VERSION ""

NS_ :

BS_:

BU_: Vector__XXX

BO_ 2416478208 M001_WriteStartLTCTransmission: 8 Vector__XXX
SG_ M001_FixValues_LockIDPageCommand : 0|24@1+ (1,0) [0|16777215] "" Vector__XXX
SG_ M001_LockIDPageCommand : 24|8@1+ (1,0) [0|255] "" Vector__XXX

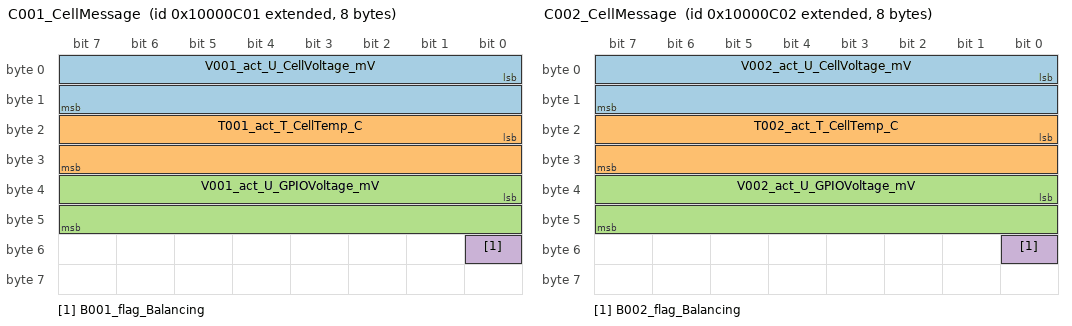
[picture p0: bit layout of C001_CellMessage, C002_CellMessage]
BO_ 2415922177 C001_CellMessage: 8 Vector__XXX
SG_ V001_act_U_CellVoltage_mV : 0|16@1+ (0.1,0) [0|6553.5] "mV" Vector__XXX
SG_ T001_act_T_CellTemp_C : 16|16@1- (0.01,0) [-327.68|327.67] "°C" Vector__XXX
SG_ V001_act_U_GPIOVoltage_mV : 32|16@1+ (0.1,0) [0|6553.5] "mV" Vector__XXX
SG_ B001_flag_Balancing : 48|1@1+ (1,0) [0|1] "" Vector__XXX

BO_ 2415922178 C002_CellMessage: 8 Vector__XXX
SG_ V002_act_U_CellVoltage_mV : 0|16@1+ (0.1,0) [0|6553.5] "mV" Vector__XXX
SG_ T002_act_T_CellTemp_C : 16|16@1- (0.01,0) [-327.68|327.67] "°C" Vector__XXX
SG_ V002_act_U_GPIOVoltage_mV : 32|16@1+ (0.1,0) [0|6553.5] "mV" Vector__XXX
SG_ B002_flag_Balancing : 48|1@1+ (1,0) [0|1] "" Vector__XXX

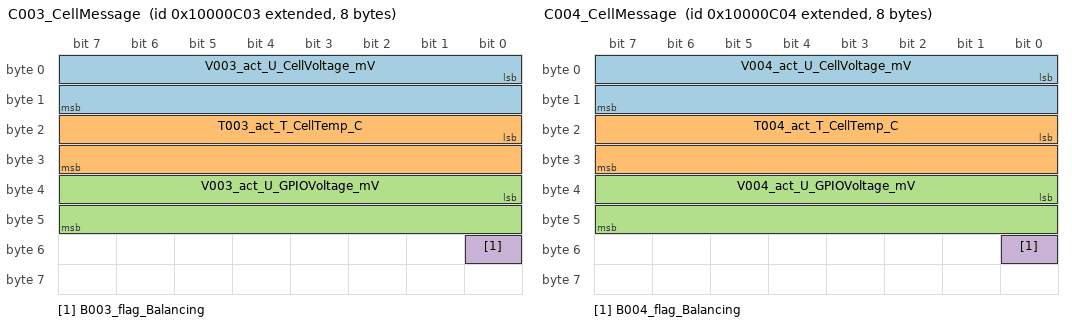
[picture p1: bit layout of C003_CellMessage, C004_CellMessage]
BO_ 2415922179 C003_CellMessage: 8 Vector__XXX
SG_ V003_act_U_CellVoltage_mV : 0|16@1+ (0.1,0) [0|6553.5] "mV" Vector__XXX
SG_ T003_act_T_CellTemp_C : 16|16@1- (0.01,0) [-327.68|327.67] "°C" Vector__XXX
SG_ V003_act_U_GPIOVoltage_mV : 32|16@1+ (0.1,0) [0|6553.5] "mV" Vector__XXX
SG_ B003_flag_Balancing : 48|1@1+ (1,0) [0|1] "" Vector__XXX

BO_ 2415922180 C004_CellMessage: 8 Vector__XXX
SG_ V004_act_U_CellVoltage_mV : 0|16@1+ (0.1,0) [0|6553.5] "mV" Vector__XXX
SG_ T004_act_T_CellTemp_C : 16|16@1- (0.01,0) [-327.68|327.67] "°C" Vector__XXX
SG_ V004_act_U_GPIOVoltage_mV : 32|16@1+ (0.1,0) [0|6553.5] "mV" Vector__XXX
SG_ B004_flag_Balancing : 48|1@1+ (1,0) [0|1] "" Vector__XXX

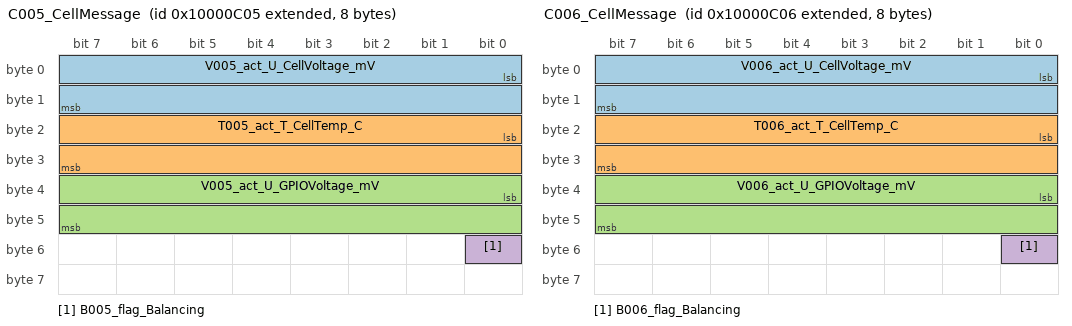
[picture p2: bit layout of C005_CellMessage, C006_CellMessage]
BO_ 2415922181 C005_CellMessage: 8 Vector__XXX
SG_ V005_act_U_CellVoltage_mV : 0|16@1+ (0.1,0) [0|6553.5] "mV" Vector__XXX
SG_ T005_act_T_CellTemp_C : 16|16@1- (0.01,0) [-327.68|327.67] "°C" Vector__XXX
SG_ V005_act_U_GPIOVoltage_mV : 32|16@1+ (0.1,0) [0|6553.5] "mV" Vector__XXX
SG_ B005_flag_Balancing : 48|1@1+ (1,0) [0|1] "" Vector__XXX

BO_ 2415922182 C006_CellMessage: 8 Vector__XXX
SG_ V006_act_U_CellVoltage_mV : 0|16@1+ (0.1,0) [0|6553.5] "mV" Vector__XXX
SG_ T006_act_T_CellTemp_C : 16|16@1- (0.01,0) [-327.68|327.67] "°C" Vector__XXX
SG_ V006_act_U_GPIOVoltage_mV : 32|16@1+ (0.1,0) [0|6553.5] "mV" Vector__XXX
SG_ B006_flag_Balancing : 48|1@1+ (1,0) [0|1] "" Vector__XXX

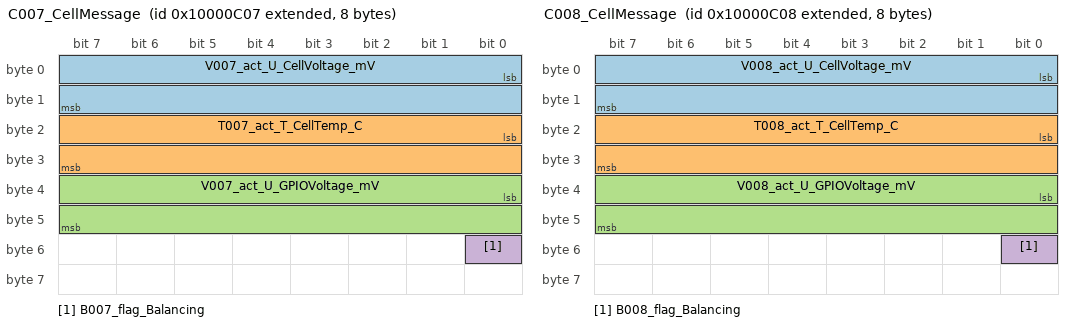
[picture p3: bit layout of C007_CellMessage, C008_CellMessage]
BO_ 2415922183 C007_CellMessage: 8 Vector__XXX
SG_ V007_act_U_CellVoltage_mV : 0|16@1+ (0.1,0) [0|6553.5] "mV" Vector__XXX
SG_ T007_act_T_CellTemp_C : 16|16@1- (0.01,0) [-327.68|327.67] "°C" Vector__XXX
SG_ V007_act_U_GPIOVoltage_mV : 32|16@1+ (0.1,0) [0|6553.5] "mV" Vector__XXX
SG_ B007_flag_Balancing : 48|1@1+ (1,0) [0|1] "" Vector__XXX

BO_ 2415922184 C008_CellMessage: 8 Vector__XXX
SG_ V008_act_U_CellVoltage_mV : 0|16@1+ (0.1,0) [0|6553.5] "mV" Vector__XXX
SG_ T008_act_T_CellTemp_C : 16|16@1- (0.01,0) [-327.68|327.67] "°C" Vector__XXX
SG_ V008_act_U_GPIOVoltage_mV : 32|16@1+ (0.1,0) [0|6553.5] "mV" Vector__XXX
SG_ B008_flag_Balancing : 48|1@1+ (1,0) [0|1] "" Vector__XXX

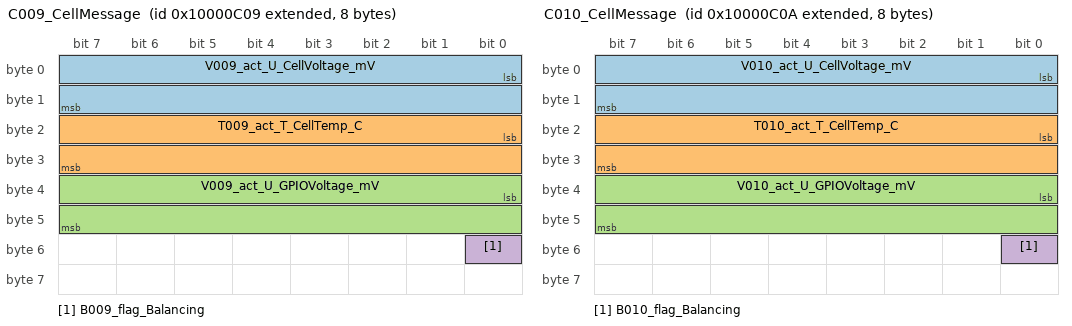
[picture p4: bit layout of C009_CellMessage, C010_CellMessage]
BO_ 2415922185 C009_CellMessage: 8 Vector__XXX
SG_ V009_act_U_CellVoltage_mV : 0|16@1+ (0.1,0) [0|6553.5] "mV" Vector__XXX
SG_ T009_act_T_CellTemp_C : 16|16@1- (0.01,0) [-327.68|327.67] "°C" Vector__XXX
SG_ V009_act_U_GPIOVoltage_mV : 32|16@1+ (0.1,0) [0|6553.5] "mV" Vector__XXX
SG_ B009_flag_Balancing : 48|1@1+ (1,0) [0|1] "" Vector__XXX

BO_ 2415922186 C010_CellMessage: 8 Vector__XXX
SG_ V010_act_U_CellVoltage_mV : 0|16@1+ (0.1,0) [0|6553.5] "mV" Vector__XXX
SG_ T010_act_T_CellTemp_C : 16|16@1- (0.01,0) [-327.68|327.67] "°C" Vector__XXX
SG_ V010_act_U_GPIOVoltage_mV : 32|16@1+ (0.1,0) [0|6553.5] "mV" Vector__XXX
SG_ B010_flag_Balancing : 48|1@1+ (1,0) [0|1] "" Vector__XXX

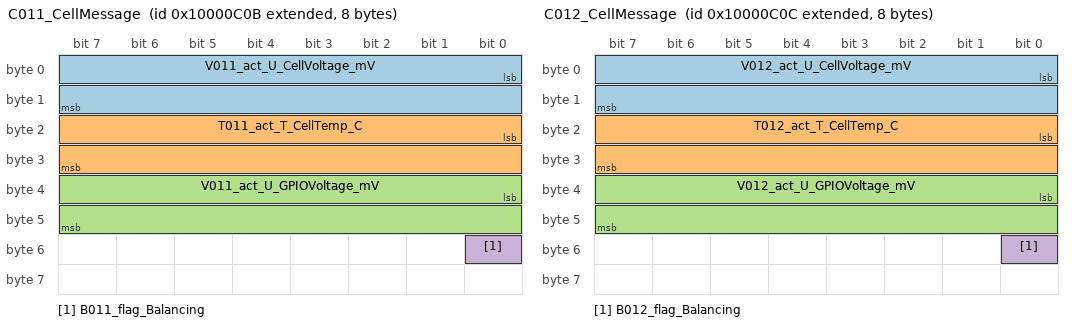
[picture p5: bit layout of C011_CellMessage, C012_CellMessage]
BO_ 2415922187 C011_CellMessage: 8 Vector__XXX
SG_ V011_act_U_CellVoltage_mV : 0|16@1+ (0.1,0) [0|6553.5] "mV" Vector__XXX
SG_ T011_act_T_CellTemp_C : 16|16@1- (0.01,0) [-327.68|327.67] "°C" Vector__XXX
SG_ V011_act_U_GPIOVoltage_mV : 32|16@1+ (0.1,0) [0|6553.5] "mV" Vector__XXX
SG_ B011_flag_Balancing : 48|1@1+ (1,0) [0|1] "" Vector__XXX

BO_ 2415922188 C012_CellMessage: 8 Vector__XXX
SG_ V012_act_U_CellVoltage_mV : 0|16@1+ (0.1,0) [0|6553.5] "mV" Vector__XXX
SG_ T012_act_T_CellTemp_C : 16|16@1- (0.01,0) [-327.68|327.67] "°C" Vector__XXX
SG_ V012_act_U_GPIOVoltage_mV : 32|16@1+ (0.1,0) [0|6553.5] "mV" Vector__XXX
SG_ B012_flag_Balancing : 48|1@1+ (1,0) [0|1] "" Vector__XXX

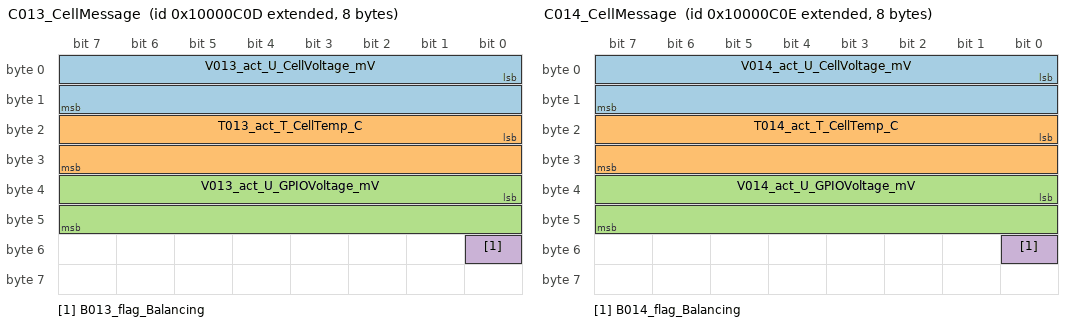
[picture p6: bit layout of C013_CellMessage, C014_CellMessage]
BO_ 2415922189 C013_CellMessage: 8 Vector__XXX
SG_ V013_act_U_CellVoltage_mV : 0|16@1+ (0.1,0) [0|6553.5] "mV" Vector__XXX
SG_ T013_act_T_CellTemp_C : 16|16@1- (0.01,0) [-327.68|327.67] "°C" Vector__XXX
SG_ V013_act_U_GPIOVoltage_mV : 32|16@1+ (0.1,0) [0|6553.5] "mV" Vector__XXX
SG_ B013_flag_Balancing : 48|1@1+ (1,0) [0|1] "" Vector__XXX

BO_ 2415922190 C014_CellMessage: 8 Vector__XXX
SG_ V014_act_U_CellVoltage_mV : 0|16@1+ (0.1,0) [0|6553.5] "mV" Vector__XXX
SG_ T014_act_T_CellTemp_C : 16|16@1- (0.01,0) [-327.68|327.67] "°C" Vector__XXX
SG_ V014_act_U_GPIOVoltage_mV : 32|16@1+ (0.1,0) [0|6553.5] "mV" Vector__XXX
SG_ B014_flag_Balancing : 48|1@1+ (1,0) [0|1] "" Vector__XXX

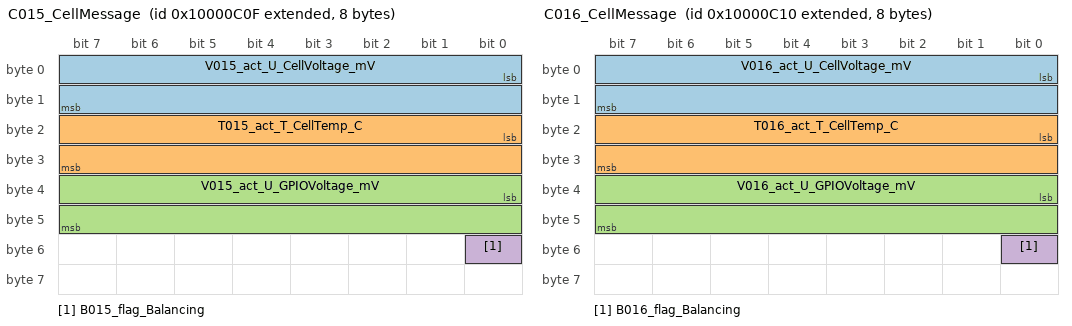
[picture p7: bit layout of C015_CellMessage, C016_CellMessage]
BO_ 2415922191 C015_CellMessage: 8 Vector__XXX
SG_ V015_act_U_CellVoltage_mV : 0|16@1+ (0.1,0) [0|6553.5] "mV" Vector__XXX
SG_ T015_act_T_CellTemp_C : 16|16@1- (0.01,0) [-327.68|327.67] "°C" Vector__XXX
SG_ V015_act_U_GPIOVoltage_mV : 32|16@1+ (0.1,0) [0|6553.5] "mV" Vector__XXX
SG_ B015_flag_Balancing : 48|1@1+ (1,0) [0|1] "" Vector__XXX

BO_ 2415922192 C016_CellMessage: 8 Vector__XXX
SG_ V016_act_U_CellVoltage_mV : 0|16@1+ (0.1,0) [0|6553.5] "mV" Vector__XXX
SG_ T016_act_T_CellTemp_C : 16|16@1- (0.01,0) [-327.68|327.67] "°C" Vector__XXX
SG_ V016_act_U_GPIOVoltage_mV : 32|16@1+ (0.1,0) [0|6553.5] "mV" Vector__XXX
SG_ B016_flag_Balancing : 48|1@1+ (1,0) [0|1] "" Vector__XXX

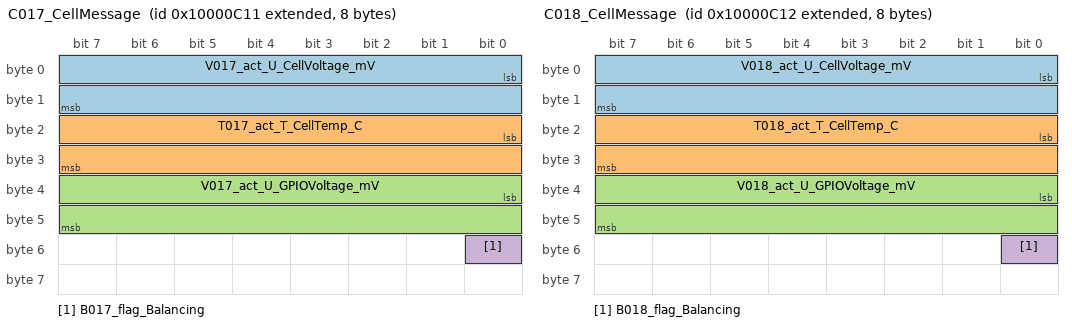
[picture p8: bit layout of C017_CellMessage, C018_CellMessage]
BO_ 2415922193 C017_CellMessage: 8 Vector__XXX
SG_ V017_act_U_CellVoltage_mV : 0|16@1+ (0.1,0) [0|6553.5] "mV" Vector__XXX
SG_ T017_act_T_CellTemp_C : 16|16@1- (0.01,0) [-327.68|327.67] "°C" Vector__XXX
SG_ V017_act_U_GPIOVoltage_mV : 32|16@1+ (0.1,0) [0|6553.5] "mV" Vector__XXX
SG_ B017_flag_Balancing : 48|1@1+ (1,0) [0|1] "" Vector__XXX

BO_ 2415922194 C018_CellMessage: 8 Vector__XXX
SG_ V018_act_U_CellVoltage_mV : 0|16@1+ (0.1,0) [0|6553.5] "mV" Vector__XXX
SG_ T018_act_T_CellTemp_C : 16|16@1- (0.01,0) [-327.68|327.67] "°C" Vector__XXX
SG_ V018_act_U_GPIOVoltage_mV : 32|16@1+ (0.1,0) [0|6553.5] "mV" Vector__XXX
SG_ B018_flag_Balancing : 48|1@1+ (1,0) [0|1] "" Vector__XXX

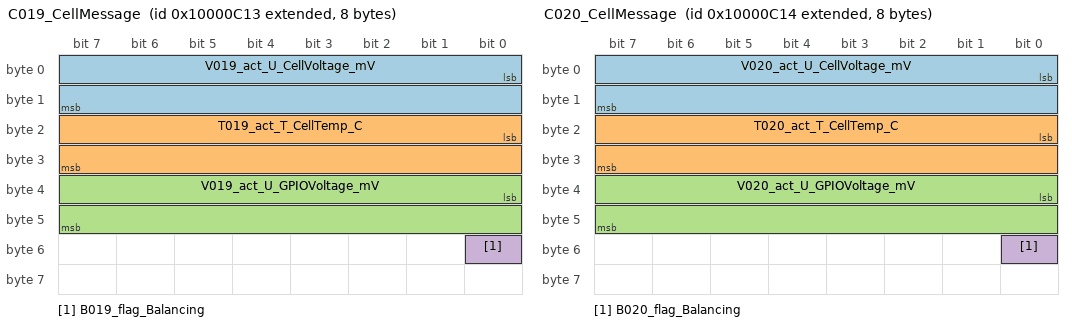
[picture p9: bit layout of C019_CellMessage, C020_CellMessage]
BO_ 2415922195 C019_CellMessage: 8 Vector__XXX
SG_ V019_act_U_CellVoltage_mV : 0|16@1+ (0.1,0) [0|6553.5] "mV" Vector__XXX
SG_ T019_act_T_CellTemp_C : 16|16@1- (0.01,0) [-327.68|327.67] "°C" Vector__XXX
SG_ V019_act_U_GPIOVoltage_mV : 32|16@1+ (0.1,0) [0|6553.5] "mV" Vector__XXX
SG_ B019_flag_Balancing : 48|1@1+ (1,0) [0|1] "" Vector__XXX

BO_ 2415922196 C020_CellMessage: 8 Vector__XXX
SG_ V020_act_U_CellVoltage_mV : 0|16@1+ (0.1,0) [0|6553.5] "mV" Vector__XXX
SG_ T020_act_T_CellTemp_C : 16|16@1- (0.01,0) [-327.68|327.67] "°C" Vector__XXX
SG_ V020_act_U_GPIOVoltage_mV : 32|16@1+ (0.1,0) [0|6553.5] "mV" Vector__XXX
SG_ B020_flag_Balancing : 48|1@1+ (1,0) [0|1] "" Vector__XXX

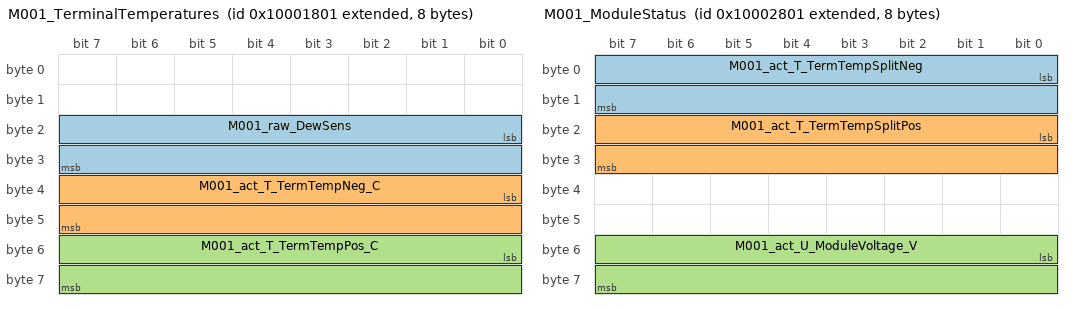
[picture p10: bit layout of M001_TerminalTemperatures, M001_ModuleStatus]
BO_ 2415925249 M001_TerminalTemperatures: 8 Vector__XXX
SG_ M001_raw_DewSens : 16|16@1+ (0.1,0) [0|6553.5] "mV" Vector__XXX
SG_ M001_act_T_TermTempNeg_C : 32|16@1- (0.01,0) [-327.68|327.67] "°C" Vector__XXX
SG_ M001_act_T_TermTempPos_C : 48|16@1- (0.01,0) [-327.68|327.67] "°C" Vector__XXX

BO_ 2415929345 M001_ModuleStatus: 8 Vector__XXX
SG_ M001_act_T_TermTempSplitNeg : 0|16@1- (0.01,0) [-327.68|327.67] "°C" Vector__XXX
SG_ M001_act_T_TermTempSplitPos : 16|16@1- (0.01,0) [-327.68|327.67] "°C" Vector__XXX
SG_ M001_act_U_ModuleVoltage_V : 48|16@1+ (0.01,0) [0|655.35] "V" Vector__XXX

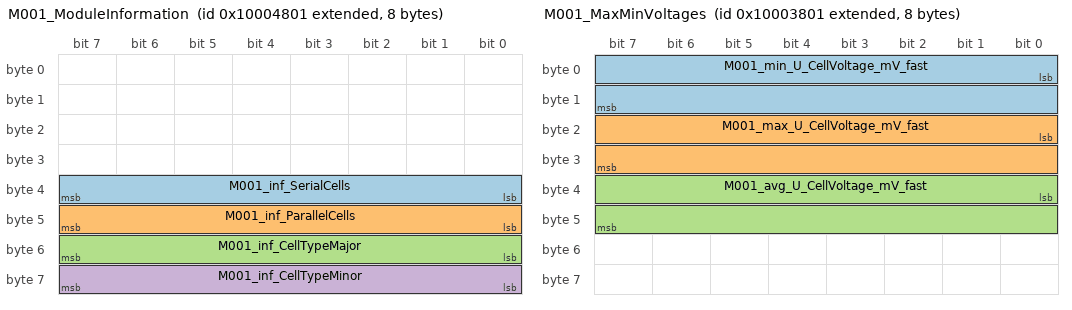
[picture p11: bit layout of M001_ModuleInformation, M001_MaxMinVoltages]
BO_ 2415937537 M001_ModuleInformation: 8 Vector__XXX
SG_ M001_inf_SerialCells : 32|8@1+ (1,0) [0|255] "" Vector__XXX
SG_ M001_inf_ParallelCells : 40|8@1+ (1,0) [0|255] "" Vector__XXX
SG_ M001_inf_CellTypeMajor : 48|8@1+ (1,0) [0|255] "" Vector__XXX
SG_ M001_inf_CellTypeMinor : 56|8@1+ (1,0) [0|255] "" Vector__XXX

BO_ 2415941633 M001_BMSInfo: 8 Vector__XXX
SG_ M001_flag_CalibrationDone : 0|1@1+ (1,0) [0|1] "" Vector__XXX
SG_ M001_flag_CalibrationIncomp : 1|1@1+ (1,0) [0|1] "" Vector__XXX
SG_ M001_flag_CalibrationError : 2|1@1+ (1,0) [0|1] "" Vector__XXX
SG_ M001_flag_EEPROMError : 4|1@1+ (1,0) [0|1] "" Vector__XXX
SG_ M001_flag_WDGError : 5|1@1+ (1,0) [0|1] "" Vector__XXX
SG_ M001_flag_ConfigDone : 6|1@1+ (1,0) [0|1] "" Vector__XXX
SG_ M001_flag_TempCalErr : 7|1@1+ (1,0) [0|1] "" Vector__XXX
SG_ M001_flag_SerialMiss : 10|1@1+ (1,0) [0|1] "" Vector__XXX
SG_ M001_flag_ThermalShtDwn_IC1 : 11|1@1+ (1,0) [0|1] "" Vector__XXX
SG_ M001_flag_ThermalShtDwn_IC2 : 12|1@1+ (1,0) [0|1] "" Vector__XXX
SG_ M001_flag_ThermalShtDwn_IC3 : 13|1@1+ (1,0) [0|1] "" Vector__XXX
SG_ M001_flag_ThermalShtDwn_IC4 : 14|1@1+ (1,0) [0|1] "" Vector__XXX
SG_ M001_flag_SelfTestPassed : 16|1@1+ (1,0) [0|1] "" Vector__XXX
SG_ M001_flag_SM_PollTimeout : 22|1@1+ (1,0) [0|1] "" Vector__XXX
SG_ M001_flag_NoSafRel_PollTimeout : 23|1@1+ (1,0) [0|1] "" Vector__XXX
SG_ M001_flag_SM_BadCRC_IC1 : 24|1@1+ (1,0) [0|1] "" Vector__XXX
SG_ M001_flag_SM_BadCRC_IC2 : 25|1@1+ (1,0) [0|1] "" Vector__XXX
SG_ M001_flag_SM_BadCRC_IC3 : 26|1@1+ (1,0) [0|1] "" Vector__XXX
SG_ M001_flag_SM_BadCRC_IC4 : 27|1@1+ (1,0) [0|1] "" Vector__XXX
SG_ M001_flag_NoSafRel_BadCRC_IC1 : 28|1@1+ (1,0) [0|1] "" Vector__XXX
SG_ M001_flag_NoSafRel_BadCRC_IC2 : 29|1@1+ (1,0) [0|1] "" Vector__XXX
SG_ M001_flag_NoSafRel_BadCRC_IC3 : 30|1@1+ (1,0) [0|1] "" Vector__XXX
SG_ M001_flag_NoSafRel_BadCRC_IC4 : 31|1@1+ (1,0) [0|1] "" Vector__XXX
SG_ M001_flag_BadCRC_IC1 : 32|1@1+ (1,0) [0|1] "" Vector__XXX
SG_ M001_flag_BadCRC_IC2 : 33|1@1+ (1,0) [0|1] "" Vector__XXX
SG_ M001_flag_BadCRC_IC3 : 34|1@1+ (1,0) [0|1] "" Vector__XXX
SG_ M001_flag_BadCRC_IC4 : 35|1@1+ (1,0) [0|1] "" Vector__XXX
SG_ M001_flag_PollTimeout : 36|1@1+ (1,0) [0|1] "" Vector__XXX
SG_ M001_flag_ComplSafAreaCRCErr : 37|1@1+ (1,0) [0|1] "" Vector__XXX
SG_ M001_flag_ComplStatAreaCRCErr : 38|1@1+ (1,0) [0|1] "" Vector__XXX
SG_ M001_flag_ComplDynAreaCRCErr : 39|1@1+ (1,0) [0|1] "" Vector__XXX
SG_ M001_flag_InitialisationFail : 40|1@1+ (1,0) [0|1] "" Vector__XXX
SG_ M001_flag_SingleSafAreaCRCErr : 41|1@1+ (1,0) [0|1] "" Vector__XXX
SG_ M001_flag_SingleStatAreaCRCErr : 42|1@1+ (1,0) [0|1] "" Vector__XXX
SG_ M001_flag_SingleDynAreaCRCErr : 43|1@1+ (1,0) [0|1] "" Vector__XXX
SG_ M001_flag_SafAreaMismatch : 44|1@1+ (1,0) [0|1] "" Vector__XXX
SG_ M001_flag_StatAreaMismatch : 45|1@1+ (1,0) [0|1] "" Vector__XXX
SG_ M001_flag_IDPageNotLocked : 46|1@1+ (1,0) [0|1] "" Vector__XXX
SG_ M001_flag_I2CCommunicationFail : 47|1@1+ (1,0) [0|1] "" Vector__XXX
SG_ M001_flag_EEPROMReadFail : 48|1@1+ (1,0) [0|1] "" Vector__XXX
SG_ M001_flag_IDPageStatusReadFail : 49|1@1+ (1,0) [0|1] "" Vector__XXX
SG_ M001_flag_SafAreaWriteFail : 50|1@1+ (1,0) [0|1] "" Vector__XXX
SG_ M001_flag_StatreaWriteFail : 51|1@1+ (1,0) [0|1] "" Vector__XXX
SG_ M001_flag_DynAreaWriteFail : 52|1@1+ (1,0) [0|1] "" Vector__XXX
SG_ M001_flag_SafAreaReadFail : 53|1@1+ (1,0) [0|1] "" Vector__XXX
SG_ M001_flag_StatAreaReadFail : 54|1@1+ (1,0) [0|1] "" Vector__XXX
SG_ M001_flag_DynAreaReadFail : 55|1@1+ (1,0) [0|1] "" Vector__XXX
SG_ M001_flag_VerifySafWriteFail : 56|1@1+ (1,0) [0|1] "" Vector__XXX
SG_ M001_flag_VerifyStatWriteFail : 57|1@1+ (1,0) [0|1] "" Vector__XXX
SG_ M001_flag_VerifyDynWriteFail : 58|1@1+ (1,0) [0|1] "" Vector__XXX

BO_ 2415986689 M001_ModuleSafetyMechanisms: 8 Vector__XXX
SG_ M001_OpenWireDetectedCV_IC1 : 0|1@1+ (1,0) [0|1] "" Vector__XXX
SG_ M001_ADCOverlapTestFailed_IC1 : 1|1@1+ (1,0) [0|1] "" Vector__XXX
SG_ M001_ADCSefttestCVFailed_IC1 : 2|1@1+ (1,0) [0|1] "" Vector__XXX
SG_ M001_ADCSefttestAUXFailed_IC1 : 3|1@1+ (1,0) [0|1] "" Vector__XXX
SG_ M001_OpenWireDetectedAUX_IC1 : 4|1@1+ (1,0) [0|1] "" Vector__XXX
SG_ M001_MUXFail_IC1 : 5|1@1+ (1,0) [0|1] "" Vector__XXX
SG_ M001_BadCRCAccepted_IC1 : 6|1@1+ (1,0) [0|1] "" Vector__XXX
SG_ M001_GPIOAdjShortDetected_IC1 : 7|1@1+ (1,0) [0|1] "" Vector__XXX
SG_ M001_CLRCmdBroken_IC1 : 8|1@1+ (1,0) [0|1] "" Vector__XXX
SG_ M001_WrongPathSelection_IC1 : 9|1@1+ (1,0) [0|1] "" Vector__XXX
SG_ M001_OWCircuitStuckCV_IC1 : 10|1@1+ (1,0) [0|1] "" Vector__XXX
SG_ M001_DischargeCircuitFault_IC1 : 11|1@1+ (1,0) [0|1] "" Vector__XXX
SG_ M001_SM_digRedFail_IC1 : 12|1@1+ (1,0) [0|1] "" Vector__XXX
SG_ M001_SM_ClrRegsFail_IC1 : 13|1@1+ (1,0) [0|1] "" Vector__XXX
SG_ M001_OpenWireDetectedCV_IC2 : 16|1@1+ (1,0) [0|1] "" Vector__XXX
SG_ M001_ADCOverlapTestFailed_IC2 : 17|1@1+ (1,0) [0|1] "" Vector__XXX
SG_ M001_ADCSefttestCVFailed_IC2 : 18|1@1+ (1,0) [0|1] "" Vector__XXX
SG_ M001_ADCSefttestAUXFailed_IC2 : 19|1@1+ (1,0) [0|1] "" Vector__XXX
SG_ M001_OpenWireDetectedAUX_IC2 : 20|1@1+ (1,0) [0|1] "" Vector__XXX
SG_ M001_MUXFail_IC2 : 21|1@1+ (1,0) [0|1] "" Vector__XXX
SG_ M001_BadCRCAccepted_IC2 : 22|1@1+ (1,0) [0|1] "" Vector__XXX
SG_ M001_GPIOAdjShortDetected_IC2 : 23|1@1+ (1,0) [0|1] "" Vector__XXX
SG_ M001_CLRCmdBroken_IC2 : 24|1@1+ (1,0) [0|1] "" Vector__XXX
SG_ M001_WrongPathSelection_IC2 : 25|1@1+ (1,0) [0|1] "" Vector__XXX
SG_ M001_OWCircuitStuckCV_IC2 : 26|1@1+ (1,0) [0|1] "" Vector__XXX
SG_ M001_DischargeCircuitFault_IC2 : 27|1@1+ (1,0) [0|1] "" Vector__XXX
SG_ M001_SM_digRedFail_IC2 : 28|1@1+ (1,0) [0|1] "" Vector__XXX
SG_ M001_SM_ClrRegsFail_IC2 : 29|1@1+ (1,0) [0|1] "" Vector__XXX
SG_ M001_OpenWireDetectedCV_IC3 : 32|1@1+ (1,0) [0|1] "" Vector__XXX
SG_ M001_ADCOverlapTestFailed_IC3 : 33|1@1+ (1,0) [0|1] "" Vector__XXX
SG_ M001_ADCSefttestCVFailed_IC3 : 34|1@1+ (1,0) [0|1] "" Vector__XXX
SG_ M001_ADCSefttestAUXFailed_IC3 : 35|1@1+ (1,0) [0|1] "" Vector__XXX
SG_ M001_OpenWireDetectedAUX_IC3 : 36|1@1+ (1,0) [0|1] "" Vector__XXX
SG_ M001_MUXFail_IC3 : 37|1@1+ (1,0) [0|1] "" Vector__XXX
SG_ M001_BadCRCAccepted_IC3 : 38|1@1+ (1,0) [0|1] "" Vector__XXX
SG_ M001_GPIOAdjShortDetected_IC3 : 39|1@1+ (1,0) [0|1] "" Vector__XXX
SG_ M001_CLRCmdBroken_IC3 : 40|1@1+ (1,0) [0|1] "" Vector__XXX
SG_ M001_WrongPathSelection_IC3 : 41|1@1+ (1,0) [0|1] "" Vector__XXX
SG_ M001_OWCircuitStuckCV_IC3 : 42|1@1+ (1,0) [0|1] "" Vector__XXX
SG_ M001_DischargeCircuitFault_IC3 : 43|1@1+ (1,0) [0|1] "" Vector__XXX
SG_ M001_SM_digRedFail_IC3 : 44|1@1+ (1,0) [0|1] "" Vector__XXX
SG_ M001_SM_ClrRegsFail_IC3 : 45|1@1+ (1,0) [0|1] "" Vector__XXX
SG_ M001_OpenWireDetectedCV_IC4 : 48|1@1+ (1,0) [0|1] "" Vector__XXX
SG_ M001_ADCOverlapTestFailed_IC4 : 49|1@1+ (1,0) [0|1] "" Vector__XXX
SG_ M001_ADCSefttestCVFailed_IC4 : 50|1@1+ (1,0) [0|1] "" Vector__XXX
SG_ M001_ADCSefttestAUXFailed_IC4 : 51|1@1+ (1,0) [0|1] "" Vector__XXX
SG_ M001_OpenWireDetectedAUX_IC4 : 52|1@1+ (1,0) [0|1] "" Vector__XXX
SG_ M001_MUXFail_IC4 : 53|1@1+ (1,0) [0|1] "" Vector__XXX
SG_ M001_BadCRCAccepted_IC4 : 54|1@1+ (1,0) [0|1] "" Vector__XXX
SG_ M001_GPIOAdjShortDetected_IC4 : 55|1@1+ (1,0) [0|1] "" Vector__XXX
SG_ M001_CLRCmdBroken_IC4 : 56|1@1+ (1,0) [0|1] "" Vector__XXX
SG_ M001_WrongPathSelection_IC4 : 57|1@1+ (1,0) [0|1] "" Vector__XXX
SG_ M001_OWCircuitStuckCV_IC4 : 58|1@1+ (1,0) [0|1] "" Vector__XXX
SG_ M001_DischargeCircuitFault_IC4 : 59|1@1+ (1,0) [0|1] "" Vector__XXX
SG_ M001_SM_digRedFail_IC4 : 60|1@1+ (1,0) [0|1] "" Vector__XXX
SG_ M001_SM_ClrRegsFail_IC4 : 61|1@1+ (1,0) [0|1] "" Vector__XXX

BO_ 2415933441 M001_MaxMinVoltages: 8 Vector__XXX
SG_ M001_min_U_CellVoltage_mV_fast : 0|16@1+ (0.1,0) [0|6553.5] "mV" Vector__XXX
SG_ M001_max_U_CellVoltage_mV_fast : 16|16@1+ (0.1,0) [0|6553.5] "mV" Vector__XXX
SG_ M001_avg_U_CellVoltage_mV_fast : 32|16@1+ (0.1,0) [0|6553.5] "mV" Vector__XXX

BO_ 2550712321 M001_CalibrationMessage: 8 Vector__XXX
SG_ M001_CalibrationMessage_Mux M : 0|32@1+ (1,0) [0|0] "" Vector__XXX
SG_ M001_conf_IdxOfTempSensor m5920170 : 32|16@1+ (1,0) [0|65535] "" Vector__XXX
SG_ M001_conf_RefTemperature_C m5920170 : 52|12@1- (0.1,0) [-204.8|204.7] "°C" Vector__XXX
SG_ M001_conf_A_CurrentOffsetA_mA m1509971370 : 32|32@1- (1,0) [-2147483648|2147483647] "mA" Vector__XXX
SG_ M001_conf_A_CurrentOffsetB_mA m1515869610 : 32|32@1- (1,0) [-2147483648|2147483647] "mA" Vector__XXX
SG_ M001_conf_A_CurrentFactorA_mA m1522226602 : 32|32@1- (1,0) [-2147483648|2147483647] "mA" Vector__XXX
SG_ M001_conf_A_CurrentFactorB_mA m3137361322 : 32|32@1- (1,0) [-2147483648|2147483647] "mA" Vector__XXX
SG_ M001_conf_U_VoltageIC1_mV m3143259562 : 32|32@1+ (1,0) [0|4294967295] "mV" Vector__XXX
SG_ M001_conf_U_VoltageIC2_mV m1527469482 : 32|32@1+ (1,0) [0|4294967295] "mV" Vector__XXX
SG_ M001_conf_U_VoltageIC3_mV m3120584106 : 32|32@1+ (1,0) [0|4294967295] "mV" Vector__XXX
SG_ M001_conf_U_VoltageIC4_mV m1522161066 : 32|32@1+ (1,0) [0|4294967295] "mV" Vector__XXX

BO_ 2550716417 M001_ConfigurationMessage: 8 Vector__XXX
SG_ M001_ConfigurationMessage_Mux M : 0|32@1+ (1,0) [0|0] "" Vector__XXX
SG_ M001_conf_NewSerialNrLo m3503336021 : 32|32@1+ (1,0) [0|4294967295] "" Vector__XXX
SG_ M001_conf_NewSerialNrHi m3671763541 : 32|32@1+ (1,0) [0|4294967295] "" Vector__XXX
SG_ M001_conf_PCBNewSerialNrLo m3671108181 : 32|32@1+ (1,0) [0|4294967295] "" Vector__XXX
SG_ M001_conf_PCBNewSerialNrHi m218999381 : 32|32@1+ (1,0) [0|4294967295] "" Vector__XXX
SG_ M001_conf_NewModuleTypeMajor m2913839701 : 32|8@1+ (1,0) [0|255] "" Vector__XXX
SG_ M001_conf_NewModuleTypeMinor m2913839701 : 40|8@1+ (1,0) [0|255] "" Vector__XXX
SG_ M001_conf_NewPCBTypeMajor m298756693 : 32|8@1+ (1,0) [0|255] "" Vector__XXX
SG_ M001_conf_NewPCBTypeMinor m298756693 : 40|8@1+ (1,0) [0|255] "" Vector__XXX
SG_ M001_conf_NewICTypeMajor m3466701397 : 32|8@1+ (1,0) [0|255] "" Vector__XXX
SG_ M001_conf_NewICTypeMinor m3466701397 : 40|8@1+ (1,0) [0|255] "" Vector__XXX
SG_ M001_conf_NewCellTypeMajor m3457264213 : 32|8@1+ (1,0) [0|255] "" Vector__XXX
SG_ M001_conf_NewCellTypeMinor m3457264213 : 40|8@1+ (1,0) [0|255] "" Vector__XXX
SG_ M001_conf_TopologyMajor m2774182485 : 32|8@1+ (1,0) [0|255] "" Vector__XXX
SG_ M001_conf_TopologyMinor m2774182485 : 40|8@1+ (1,0) [0|255] "" Vector__XXX

BO_ 2451052545 M001_BalanceCells: 8 Vector__XXX
SG_ M001_flag_BalanceCell1 : 0|1@1+ (1,0) [0|1] "" Vector__XXX
SG_ M001_flag_BalanceCell2 : 1|1@1+ (1,0) [0|1] "" Vector__XXX
SG_ M001_flag_BalanceCell3 : 2|1@1+ (1,0) [0|1] "" Vector__XXX
SG_ M001_flag_BalanceCell4 : 3|1@1+ (1,0) [0|1] "" Vector__XXX
SG_ M001_flag_BalanceCell5 : 4|1@1+ (1,0) [0|1] "" Vector__XXX
SG_ M001_flag_BalanceCell6 : 5|1@1+ (1,0) [0|1] "" Vector__XXX
SG_ M001_flag_BalanceCell7 : 6|1@1+ (1,0) [0|1] "" Vector__XXX
SG_ M001_flag_BalanceCell8 : 7|1@1+ (1,0) [0|1] "" Vector__XXX
SG_ M001_flag_BalanceCell9 : 8|1@1+ (1,0) [0|1] "" Vector__XXX
SG_ M001_flag_BalanceCell10 : 9|1@1+ (1,0) [0|1] "" Vector__XXX
SG_ M001_flag_BalanceCell11 : 10|1@1+ (1,0) [0|1] "" Vector__XXX
SG_ M001_flag_BalanceCell12 : 11|1@1+ (1,0) [0|1] "" Vector__XXX
SG_ M001_flag_BalanceCell13 : 12|1@1+ (1,0) [0|1] "" Vector__XXX
SG_ M001_flag_BalanceCell14 : 13|1@1+ (1,0) [0|1] "" Vector__XXX
SG_ M001_flag_BalanceCell15 : 14|1@1+ (1,0) [0|1] "" Vector__XXX
SG_ M001_flag_BalanceCell16 : 15|1@1+ (1,0) [0|1] "" Vector__XXX
SG_ M001_flag_BalanceCell17 : 16|1@1+ (1,0) [0|1] "" Vector__XXX
SG_ M001_flag_BalanceCell18 : 17|1@1+ (1,0) [0|1] "" Vector__XXX
SG_ M001_flag_BalanceCell19 : 18|1@1+ (1,0) [0|1] "" Vector__XXX
SG_ M001_flag_BalanceCell20 : 19|1@1+ (1,0) [0|1] "" Vector__XXX
SG_ M001_flag_BalanceCell21 : 20|1@1+ (1,0) [0|1] "" Vector__XXX
SG_ M001_flag_BalanceCell22 : 21|1@1+ (1,0) [0|1] "" Vector__XXX
SG_ M001_flag_BalanceCell23 : 22|1@1+ (1,0) [0|1] "" Vector__XXX
SG_ M001_flag_BalanceCell24 : 23|1@1+ (1,0) [0|1] "" Vector__XXX
SG_ M001_flag_BalanceCell25 : 24|1@1+ (1,0) [0|1] "" Vector__XXX
SG_ M001_flag_BalanceCell26 : 25|1@1+ (1,0) [0|1] "" Vector__XXX
SG_ M001_flag_BalanceCell27 : 26|1@1+ (1,0) [0|1] "" Vector__XXX
SG_ M001_flag_BalanceCell28 : 27|1@1+ (1,0) [0|1] "" Vector__XXX
SG_ M001_flag_BalanceCell29 : 28|1@1+ (1,0) [0|1] "" Vector__XXX
SG_ M001_flag_BalanceCell30 : 29|1@1+ (1,0) [0|1] "" Vector__XXX
SG_ M001_flag_BalanceCell31 : 30|1@1+ (1,0) [0|1] "" Vector__XXX
SG_ M001_flag_BalanceCell32 : 31|1@1+ (1,0) [0|1] "" Vector__XXX

BO_ 2415945729 M001_SlaveSerials: 8 Vector__XXX
SG_ M001_SlaveSerials_Mux M : 62|2@1+ (1,0) [0|0] "" Vector__XXX
SG_ M001_Aka_FunctionArea_P m0 : 58|4@1+ (1,0) [0|15] "" Vector__XXX
SG_ M001_Aka_Year_P m0 : 51|7@1+ (1,0) [0|127] "" Vector__XXX
SG_ M001_Aka_Week_P m0 : 45|6@1+ (1,0) [0|63] "" Vector__XXX
SG_ M001_Aka_Plant m0 : 38|7@1+ (1,0) [0|127] "" Vector__XXX
SG_ M001_Aka_Line m0 : 31|7@1+ (1,0) [0|127] "" Vector__XXX
SG_ M001_Aka_Los_No_P m0 : 0|31@1+ (1,0) [0|2147483647] "" Vector__XXX
SG_ M001_Aka_FunctionArea_E m1 : 58|4@1+ (1,0) [0|15] "" Vector__XXX
SG_ M001_Aka_Year_E m1 : 51|7@1+ (1,0) [0|127] "" Vector__XXX
SG_ M001_Aka_Week_E m1 : 45|6@1+ (1,0) [0|63] "" Vector__XXX
SG_ M001_Aka_Module m1 : 31|14@1+ (1,0) [0|16383] "" Vector__XXX
SG_ M001_Aka_Version m1 : 24|7@1+ (1,0) [0|127] "" Vector__XXX
SG_ M001_Aka_Supplier m1 : 14|10@1+ (1,0) [0|1023] "" Vector__XXX
SG_ M001_Aka_Los_No_E m1 : 0|13@1+ (1,0) [0|8191] "" Vector__XXX

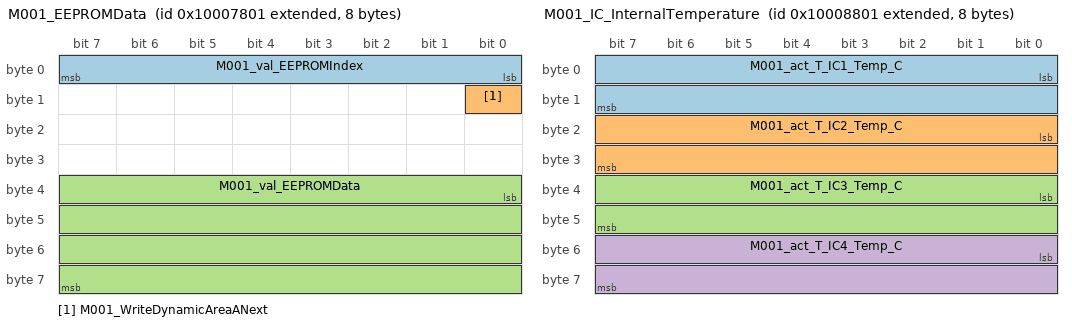
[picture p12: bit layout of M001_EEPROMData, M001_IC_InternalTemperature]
BO_ 2415949825 M001_EEPROMData: 8 Vector__XXX
SG_ M001_val_EEPROMIndex : 0|8@1+ (1,0) [0|255] "" Vector__XXX
SG_ M001_WriteDynamicAreaANext : 8|1@1+ (1,0) [0|1] "" Vector__XXX
SG_ M001_val_EEPROMData : 32|32@1+ (1,0) [0|4294967295] "" Vector__XXX

BO_ 2416474113 M001_WriteEEPROMData: 8 Vector__XXX
SG_ M001_WriteEEPROMData_Mux M : 0|24@1+ (1,0) [0|0] "" Vector__XXX
SG_ M001_val_EEPROMWriteIndex m14318101 : 24|8@1+ (1,0) [0|255] "" Vector__XXX
SG_ M001_val_EEPROMWriteData m14318101 : 32|32@1+ (1,0) [0|4294967295] "" Vector__XXX

BO_ 2416482305 M001_EEPROMChangeDynArea: 8 Vector__XXX
SG_ M001_val_Magic : 0|24@1+ (1,0) [0|16777215] "" Vector__XXX
SG_ M001_WriteDynamicAreaANext : 24|1@1+ (1,0) [0|1] "" Vector__XXX

BO_ 2416478209 M001_StartLTCTransmission: 8 Vector__XXX
SG_ M001_val_Magic : 0|24@1+ (1,0) [0|16777215] "" Vector__XXX

BO_ 2415953921 M001_IC_InternalTemperature: 8 Vector__XXX
SG_ M001_act_T_IC1_Temp_C : 0|16@1- (0.01,0) [-327.68|327.67] "°C" Vector__XXX
SG_ M001_act_T_IC2_Temp_C : 16|16@1- (0.01,0) [-327.68|327.67] "°C" Vector__XXX
SG_ M001_act_T_IC3_Temp_C : 32|16@1- (0.01,0) [-327.68|327.67] "°C" Vector__XXX
SG_ M001_act_T_IC4_Temp_C : 48|16@1- (0.01,0) [-327.68|327.67] "°C" Vector__XXX

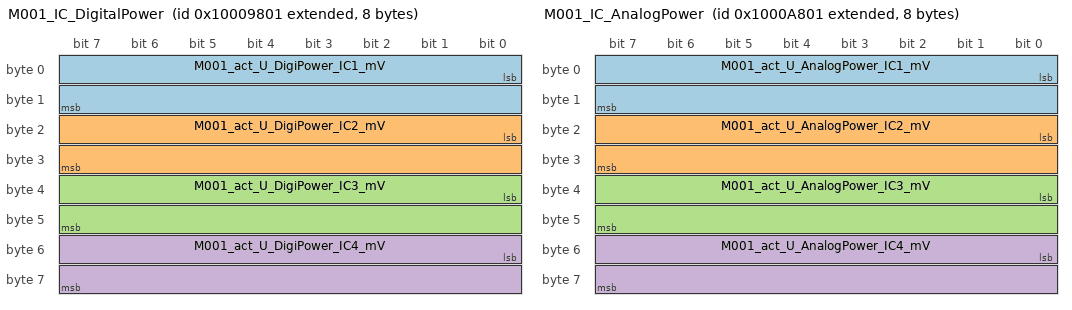
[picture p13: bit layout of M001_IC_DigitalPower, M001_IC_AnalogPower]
BO_ 2415958017 M001_IC_DigitalPower: 8 Vector__XXX
SG_ M001_act_U_DigiPower_IC1_mV : 0|16@1+ (0.1,0) [0|6553.5] "mV" Vector__XXX
SG_ M001_act_U_DigiPower_IC2_mV : 16|16@1+ (0.1,0) [0|6553.5] "mV" Vector__XXX
SG_ M001_act_U_DigiPower_IC3_mV : 32|16@1+ (0.1,0) [0|6553.5] "mV" Vector__XXX
SG_ M001_act_U_DigiPower_IC4_mV : 48|16@1+ (0.1,0) [0|6553.5] "mV" Vector__XXX

BO_ 2415962113 M001_IC_AnalogPower: 8 Vector__XXX
SG_ M001_act_U_AnalogPower_IC1_mV : 0|16@1+ (0.1,0) [0|6553.5] "mV" Vector__XXX
SG_ M001_act_U_AnalogPower_IC2_mV : 16|16@1+ (0.1,0) [0|6553.5] "mV" Vector__XXX
SG_ M001_act_U_AnalogPower_IC3_mV : 32|16@1+ (0.1,0) [0|6553.5] "mV" Vector__XXX
SG_ M001_act_U_AnalogPower_IC4_mV : 48|16@1+ (0.1,0) [0|6553.5] "mV" Vector__XXX

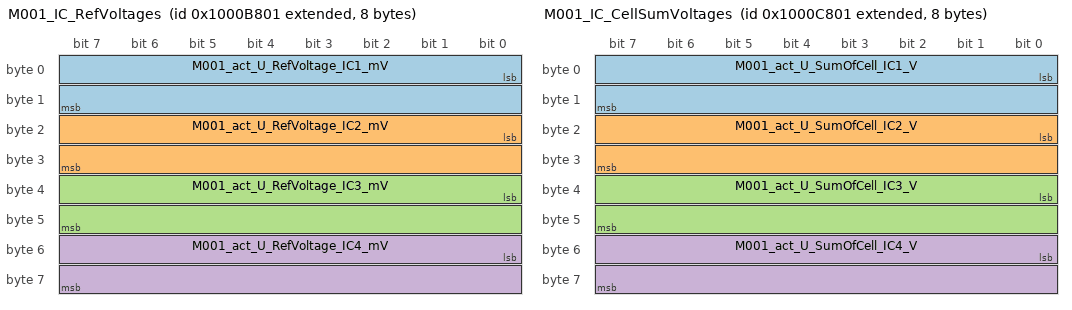
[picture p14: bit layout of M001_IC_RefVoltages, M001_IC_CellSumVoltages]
BO_ 2415966209 M001_IC_RefVoltages: 8 Vector__XXX
SG_ M001_act_U_RefVoltage_IC1_mV : 0|16@1+ (0.1,0) [0|6553.5] "mV" Vector__XXX
SG_ M001_act_U_RefVoltage_IC2_mV : 16|16@1+ (0.1,0) [0|6553.5] "mV" Vector__XXX
SG_ M001_act_U_RefVoltage_IC3_mV : 32|16@1+ (0.1,0) [0|6553.5] "mV" Vector__XXX
SG_ M001_act_U_RefVoltage_IC4_mV : 48|16@1+ (0.1,0) [0|6553.5] "mV" Vector__XXX

BO_ 2415970305 M001_IC_CellSumVoltages: 8 Vector__XXX
SG_ M001_act_U_SumOfCell_IC1_V : 0|16@1+ (0.01,0) [0|655.35] "V" Vector__XXX
SG_ M001_act_U_SumOfCell_IC2_V : 16|16@1+ (0.01,0) [0|655.35] "V" Vector__XXX
SG_ M001_act_U_SumOfCell_IC3_V : 32|16@1+ (0.01,0) [0|655.35] "V" Vector__XXX
SG_ M001_act_U_SumOfCell_IC4_V : 48|16@1+ (0.01,0) [0|655.35] "V" Vector__XXX

BO_ 2415974401 M001_OverVoltageFlags: 8 Vector__XXX
SG_ M001_flag_OvervoltageCell1 : 0|1@1+ (1,0) [0|1] "" Vector__XXX
SG_ M001_flag_OvervoltageCell2 : 1|1@1+ (1,0) [0|1] "" Vector__XXX
SG_ M001_flag_OvervoltageCell3 : 2|1@1+ (1,0) [0|1] "" Vector__XXX
SG_ M001_flag_OvervoltageCell4 : 3|1@1+ (1,0) [0|1] "" Vector__XXX
SG_ M001_flag_OvervoltageCell5 : 4|1@1+ (1,0) [0|1] "" Vector__XXX
SG_ M001_flag_OvervoltageCell6 : 5|1@1+ (1,0) [0|1] "" Vector__XXX
SG_ M001_flag_OvervoltageCell7 : 6|1@1+ (1,0) [0|1] "" Vector__XXX
SG_ M001_flag_OvervoltageCell8 : 7|1@1+ (1,0) [0|1] "" Vector__XXX
SG_ M001_flag_OvervoltageCell9 : 8|1@1+ (1,0) [0|1] "" Vector__XXX
SG_ M001_flag_OvervoltageCell10 : 9|1@1+ (1,0) [0|1] "" Vector__XXX
SG_ M001_flag_OvervoltageCell11 : 10|1@1+ (1,0) [0|1] "" Vector__XXX
SG_ M001_flag_OvervoltageCell12 : 11|1@1+ (1,0) [0|1] "" Vector__XXX
SG_ M001_flag_OvervoltageCell13 : 12|1@1+ (1,0) [0|1] "" Vector__XXX
SG_ M001_flag_OvervoltageCell14 : 13|1@1+ (1,0) [0|1] "" Vector__XXX
SG_ M001_flag_OvervoltageCell15 : 14|1@1+ (1,0) [0|1] "" Vector__XXX
SG_ M001_flag_OvervoltageCell16 : 15|1@1+ (1,0) [0|1] "" Vector__XXX
SG_ M001_flag_OvervoltageCell17 : 16|1@1+ (1,0) [0|1] "" Vector__XXX
SG_ M001_flag_OvervoltageCell18 : 17|1@1+ (1,0) [0|1] "" Vector__XXX
SG_ M001_flag_OvervoltageCell19 : 18|1@1+ (1,0) [0|1] "" Vector__XXX
SG_ M001_flag_OvervoltageCell20 : 19|1@1+ (1,0) [0|1] "" Vector__XXX
SG_ M001_flag_OvervoltageCell21 : 20|1@1+ (1,0) [0|1] "" Vector__XXX
SG_ M001_flag_OvervoltageCell22 : 21|1@1+ (1,0) [0|1] "" Vector__XXX
SG_ M001_flag_OvervoltageCell23 : 22|1@1+ (1,0) [0|1] "" Vector__XXX
SG_ M001_flag_OvervoltageCell24 : 23|1@1+ (1,0) [0|1] "" Vector__XXX
SG_ M001_flag_OvervoltageCell25 : 24|1@1+ (1,0) [0|1] "" Vector__XXX
SG_ M001_flag_OvervoltageCell26 : 25|1@1+ (1,0) [0|1] "" Vector__XXX
SG_ M001_flag_OvervoltageCell27 : 26|1@1+ (1,0) [0|1] "" Vector__XXX
SG_ M001_flag_OvervoltageCell28 : 27|1@1+ (1,0) [0|1] "" Vector__XXX
SG_ M001_flag_OvervoltageCell29 : 28|1@1+ (1,0) [0|1] "" Vector__XXX
SG_ M001_flag_OvervoltageCell30 : 29|1@1+ (1,0) [0|1] "" Vector__XXX
SG_ M001_flag_OvervoltageCell31 : 30|1@1+ (1,0) [0|1] "" Vector__XXX
SG_ M001_flag_OvervoltageCell32 : 31|1@1+ (1,0) [0|1] "" Vector__XXX
SG_ M001_flag_OvervoltageCell33 : 32|1@1+ (1,0) [0|1] "" Vector__XXX
SG_ M001_flag_OvervoltageCell34 : 33|1@1+ (1,0) [0|1] "" Vector__XXX
SG_ M001_flag_OvervoltageCell35 : 34|1@1+ (1,0) [0|1] "" Vector__XXX
SG_ M001_flag_OvervoltageCell36 : 35|1@1+ (1,0) [0|1] "" Vector__XXX
SG_ M001_flag_OvervoltageCell37 : 36|1@1+ (1,0) [0|1] "" Vector__XXX
SG_ M001_flag_OvervoltageCell38 : 37|1@1+ (1,0) [0|1] "" Vector__XXX
SG_ M001_flag_OvervoltageCell39 : 38|1@1+ (1,0) [0|1] "" Vector__XXX
SG_ M001_flag_OvervoltageCell40 : 39|1@1+ (1,0) [0|1] "" Vector__XXX

BO_ 2415978497 M001_UnderVoltageFlags: 8 Vector__XXX
SG_ M001_flag_UndervoltageCell1 : 0|1@1+ (1,0) [0|1] "" Vector__XXX
SG_ M001_flag_UndervoltageCell2 : 1|1@1+ (1,0) [0|1] "" Vector__XXX
SG_ M001_flag_UndervoltageCell3 : 2|1@1+ (1,0) [0|1] "" Vector__XXX
SG_ M001_flag_UndervoltageCell4 : 3|1@1+ (1,0) [0|1] "" Vector__XXX
SG_ M001_flag_UndervoltageCell5 : 4|1@1+ (1,0) [0|1] "" Vector__XXX
SG_ M001_flag_UndervoltageCell6 : 5|1@1+ (1,0) [0|1] "" Vector__XXX
SG_ M001_flag_UndervoltageCell7 : 6|1@1+ (1,0) [0|1] "" Vector__XXX
SG_ M001_flag_UndervoltageCell8 : 7|1@1+ (1,0) [0|1] "" Vector__XXX
SG_ M001_flag_UndervoltageCell9 : 8|1@1+ (1,0) [0|1] "" Vector__XXX
SG_ M001_flag_UndervoltageCell10 : 9|1@1+ (1,0) [0|1] "" Vector__XXX
SG_ M001_flag_UndervoltageCell11 : 10|1@1+ (1,0) [0|1] "" Vector__XXX
SG_ M001_flag_UndervoltageCell12 : 11|1@1+ (1,0) [0|1] "" Vector__XXX
SG_ M001_flag_UndervoltageCell13 : 12|1@1+ (1,0) [0|1] "" Vector__XXX
SG_ M001_flag_UndervoltageCell14 : 13|1@1+ (1,0) [0|1] "" Vector__XXX
SG_ M001_flag_UndervoltageCell15 : 14|1@1+ (1,0) [0|1] "" Vector__XXX
SG_ M001_flag_UndervoltageCell16 : 15|1@1+ (1,0) [0|1] "" Vector__XXX
SG_ M001_flag_UndervoltageCell17 : 16|1@1+ (1,0) [0|1] "" Vector__XXX
SG_ M001_flag_UndervoltageCell18 : 17|1@1+ (1,0) [0|1] "" Vector__XXX
SG_ M001_flag_UndervoltageCell19 : 18|1@1+ (1,0) [0|1] "" Vector__XXX
SG_ M001_flag_UndervoltageCell20 : 19|1@1+ (1,0) [0|1] "" Vector__XXX
SG_ M001_flag_UndervoltageCell21 : 20|1@1+ (1,0) [0|1] "" Vector__XXX
SG_ M001_flag_UndervoltageCell22 : 21|1@1+ (1,0) [0|1] "" Vector__XXX
SG_ M001_flag_UndervoltageCell23 : 22|1@1+ (1,0) [0|1] "" Vector__XXX
SG_ M001_flag_UndervoltageCell24 : 23|1@1+ (1,0) [0|1] "" Vector__XXX
SG_ M001_flag_UndervoltageCell25 : 24|1@1+ (1,0) [0|1] "" Vector__XXX
SG_ M001_flag_UndervoltageCell26 : 25|1@1+ (1,0) [0|1] "" Vector__XXX
SG_ M001_flag_UndervoltageCell27 : 26|1@1+ (1,0) [0|1] "" Vector__XXX
SG_ M001_flag_UndervoltageCell28 : 27|1@1+ (1,0) [0|1] "" Vector__XXX
SG_ M001_flag_UndervoltageCell29 : 28|1@1+ (1,0) [0|1] "" Vector__XXX
SG_ M001_flag_UndervoltageCell30 : 29|1@1+ (1,0) [0|1] "" Vector__XXX
SG_ M001_flag_UndervoltageCell31 : 30|1@1+ (1,0) [0|1] "" Vector__XXX
SG_ M001_flag_UndervoltageCell32 : 31|1@1+ (1,0) [0|1] "" Vector__XXX
SG_ M001_flag_UndervoltageCell33 : 32|1@1+ (1,0) [0|1] "" Vector__XXX
SG_ M001_flag_UndervoltageCell34 : 33|1@1+ (1,0) [0|1] "" Vector__XXX
SG_ M001_flag_UndervoltageCell35 : 34|1@1+ (1,0) [0|1] "" Vector__XXX
SG_ M001_flag_UndervoltageCell36 : 35|1@1+ (1,0) [0|1] "" Vector__XXX
SG_ M001_flag_UndervoltageCell37 : 36|1@1+ (1,0) [0|1] "" Vector__XXX
SG_ M001_flag_UndervoltageCell38 : 37|1@1+ (1,0) [0|1] "" Vector__XXX
SG_ M001_flag_UndervoltageCell39 : 38|1@1+ (1,0) [0|1] "" Vector__XXX
SG_ M001_flag_UndervoltageCell40 : 39|1@1+ (1,0) [0|1] "" Vector__XXX

BO_ 2415982593 M001_SendEEPROMDataEOL: 8 Vector__XXX
SG_ M001_SendEEPROMDataEOL_Mux M : 0|32@1+ (1,0) [0|0] "" Vector__XXX
SG_ M001_conf_IdxOfTempSensor m5920170 : 32|16@1+ (1,0) [0|65535] "" Vector__XXX
SG_ M001_conf_RefTemperature_C m5920170 : 52|12@1- (0.1,0) [-204.8|204.7] "°C" Vector__XXX
SG_ M001_conf_A_CurrentOffsetA_mA m1509971370 : 32|32@1- (1,0) [-2147483648|2147483647] "mA" Vector__XXX
SG_ M001_conf_A_CurrentOffsetB_mA m1515869610 : 32|32@1- (1,0) [-2147483648|2147483647] "mA" Vector__XXX
SG_ M001_conf_A_CurrentFactorA_mA m1522226602 : 32|32@1- (1,0) [-2147483648|2147483647] "mA" Vector__XXX
SG_ M001_conf_A_CurrentFactorB_mA m3137361322 : 32|32@1- (1,0) [-2147483648|2147483647] "mA" Vector__XXX
SG_ M001_conf_U_VoltageIC1_mV m3143259562 : 32|32@1+ (1,0) [0|4294967295] "mV" Vector__XXX
SG_ M001_conf_U_VoltageIC2_mV m1527469482 : 32|32@1+ (1,0) [0|4294967295] "mV" Vector__XXX
SG_ M001_conf_U_VoltageIC3_mV m3120584106 : 32|32@1+ (1,0) [0|4294967295] "mV" Vector__XXX
SG_ M001_conf_U_VoltageIC4_mV m1522161066 : 32|32@1+ (1,0) [0|4294967295] "mV" Vector__XXX
SG_ M001_conf_NewSerialNrLo m3503336021 : 32|32@1+ (1,0) [0|4294967295] "" Vector__XXX
SG_ M001_conf_NewSerialNrHi m3671763541 : 32|32@1+ (1,0) [0|4294967295] "" Vector__XXX
SG_ M001_conf_PCBNewSerialNrLo m3671108181 : 32|32@1+ (1,0) [0|4294967295] "" Vector__XXX
SG_ M001_conf_PCBNewSerialNrHi m218999381 : 32|32@1+ (1,0) [0|4294967295] "" Vector__XXX
SG_ M001_conf_NewModuleTypeMajor m2913839701 : 32|8@1+ (1,0) [0|255] "" Vector__XXX
SG_ M001_conf_NewModuleTypeMinor m2913839701 : 40|8@1+ (1,0) [0|255] "" Vector__XXX
SG_ M001_conf_NewPCBTypeMajor m298756693 : 32|8@1+ (1,0) [0|255] "" Vector__XXX
SG_ M001_conf_NewPCBTypeMinor m298756693 : 40|8@1+ (1,0) [0|255] "" Vector__XXX
SG_ M001_conf_NewICTypeMajor m3466701397 : 32|8@1+ (1,0) [0|255] "" Vector__XXX
SG_ M001_conf_NewICTypeMinor m3466701397 : 40|8@1+ (1,0) [0|255] "" Vector__XXX
SG_ M001_conf_NewCellTypeMajor m3457264213 : 32|8@1+ (1,0) [0|255] "" Vector__XXX
SG_ M001_conf_NewCellTypeMinor m3457264213 : 40|8@1+ (1,0) [0|255] "" Vector__XXX
SG_ M001_conf_TopologyMajor m2774182485 : 32|8@1+ (1,0) [0|255] "" Vector__XXX
SG_ M001_conf_TopologyMinor m2774182485 : 40|8@1+ (1,0) [0|255] "" Vector__XXX

BO_ 2281706497 SCU1_Status: 8 Vector__XXX
SG_ SCU1_stat_Init : 0|1@1+ (1,0) [0|1] "" Vector__XXX
SG_ SCU1_stat_Run : 1|1@1+ (1,0) [0|1] "" Vector__XXX
SG_ SCU1_stat_Error : 2|1@1+ (1,0) [0|1] "" Vector__XXX
SG_ SCU1_stat_Config : 3|1@1+ (1,0) [0|1] "" Vector__XXX
SG_ SCU1_stat_LimpHome : 4|1@1+ (1,0) [0|1] "" Vector__XXX
SG_ SCU1_stat_Diag : 5|1@1+ (1,0) [0|1] "" Vector__XXX
SG_ SCU1_stat_Shutdown : 8|1@1+ (1,0) [0|1] "" Vector__XXX
SG_ SCU1_stat_ART_Started : 9|1@1+ (1,0) [0|1] "" Vector__XXX
SG_ SCU1_stat_ART_IsActive : 10|1@1+ (1,0) [0|1] "" Vector__XXX
SG_ SCU1_stat_ART_NoError : 11|1@1+ (1,0) [0|1] "" Vector__XXX
SG_ SCU1_stat_ART_BMSS_Restart : 12|1@1+ (1,0) [0|1] "" Vector__XXX
SG_ SCU1_flag_PowerContPos : 16|1@1+ (1,0) [0|1] "" Vector__XXX
SG_ SCU1_flag_PowerContNeg : 17|1@1+ (1,0) [0|1] "" Vector__XXX
SG_ SCU1_flag_PowerContPre : 18|1@1+ (1,0) [0|1] "" Vector__XXX
SG_ SCU1_flag_PowerContExtAux : 19|1@1+ (1,0) [0|1] "" Vector__XXX
SG_ SCU1_stat_ConOnProtect : 20|1@1+ (1,0) [0|1] "" Vector__XXX
SG_ SCU1_flag_ShuntResCalibration : 22|1@1+ (1,0) [0|1] "" Vector__XXX
SG_ SCU1_flag_EoL_Mode : 23|1@1+ (1,0) [0|1] "" Vector__XXX
SG_ SCU1_flag_VSenserelayPosInt : 24|1@1+ (1,0) [0|1] "" Vector__XXX
SG_ SCU1_flag_VSenserelayNegInt : 25|1@1+ (1,0) [0|1] "" Vector__XXX
SG_ SCU1_flag_VSenserelayPosExt : 26|1@1+ (1,0) [0|1] "" Vector__XXX
SG_ SCU1_flag_VSenserelayNegExt : 27|1@1+ (1,0) [0|1] "" Vector__XXX
SG_ SCU1_flag_eStopLoopNotClosed : 32|1@1+ (1,0) [0|1] "" Vector__XXX
SG_ SCU1_flag_InterventioneStop : 33|1@1+ (1,0) [0|1] "" Vector__XXX
SG_ SCU1_flag_InterLockError : 34|1@1+ (1,0) [0|1] "" Vector__XXX
SG_ SCU1_flag_SourceInterlockLoop : 35|1@1+ (1,0) [0|1] "" Vector__XXX
SG_ SCU1_flag_KL15 : 36|1@1+ (1,0) [0|1] "" Vector__XXX
SG_ SCU1_flag_BMMSafe : 37|1@1+ (1,0) [0|1] "" Vector__XXX
SG_ SCU1_flag_SupplyMonitorWarning : 38|1@1+ (1,0) [0|1] "" Vector__XXX
SG_ SCU1_flag_CANGatewayStatus : 39|1@1+ (1,0) [0|1] "" Vector__XXX
SG_ SCU1_flag_Led1 : 40|1@1+ (1,0) [0|1] "" Vector__XXX
SG_ SCU1_flag_Led2 : 41|1@1+ (1,0) [0|1] "" Vector__XXX
SG_ SCU1_flag_Led3 : 42|1@1+ (1,0) [0|1] "" Vector__XXX
SG_ SCU1_flag_Warning : 43|1@1+ (1,0) [0|1] "" Vector__XXX
SG_ SCU1_flag_Alarm : 44|1@1+ (1,0) [0|1] "" Vector__XXX
SG_ SCU1_flag_SilentCan1 : 45|1@1+ (1,0) [0|1] "" Vector__XXX
SG_ SCU1_flag_SilentCan2 : 46|1@1+ (1,0) [0|1] "" Vector__XXX
SG_ SCU1_flag_HSS1Locked : 48|1@1+ (1,0) [0|1] "" Vector__XXX
SG_ SCU1_flag_HSS2Locked : 49|1@1+ (1,0) [0|1] "" Vector__XXX
SG_ SCU1_flag_HSS3Locked : 50|1@1+ (1,0) [0|1] "" Vector__XXX
SG_ SCU1_flag_HSS4Locked : 51|1@1+ (1,0) [0|1] "" Vector__XXX
SG_ SCU1_flag_CompChipWarning : 52|1@1+ (1,0) [0|1] "" Vector__XXX
SG_ SCU1_flag_PowerProtWarning : 53|1@1+ (1,0) [0|1] "" Vector__XXX
SG_ SCU1_flag_SafetyEnable1 : 54|1@1+ (1,0) [0|1] "" Vector__XXX
SG_ SCU1_flag_SafetyEnable2 : 55|1@1+ (1,0) [0|1] "" Vector__XXX
SG_ SCU1_flag_eStopBrakeOut : 56|1@1+ (1,0) [0|1] "" Vector__XXX
SG_ SCU1_flag_ForceSave : 57|1@1+ (1,0) [0|1] "" Vector__XXX
SG_ SCU1_flag_CAN1BusOff : 58|1@1+ (1,0) [0|1] "" Vector__XXX
SG_ SCU1_flag_CAN2BusOff : 59|1@1+ (1,0) [0|1] "" Vector__XXX
SG_ SCU1_flag_ContStuckChk : 60|1@1+ (1,0) [0|1] "" Vector__XXX
SG_ SCU1_flag_ExtAuxStuckChk : 61|1@1+ (1,0) [0|1] "" Vector__XXX
SG_ SCU1_flag_PrechargeOK : 63|1@1+ (1,0) [0|1] "" Vector__XXX

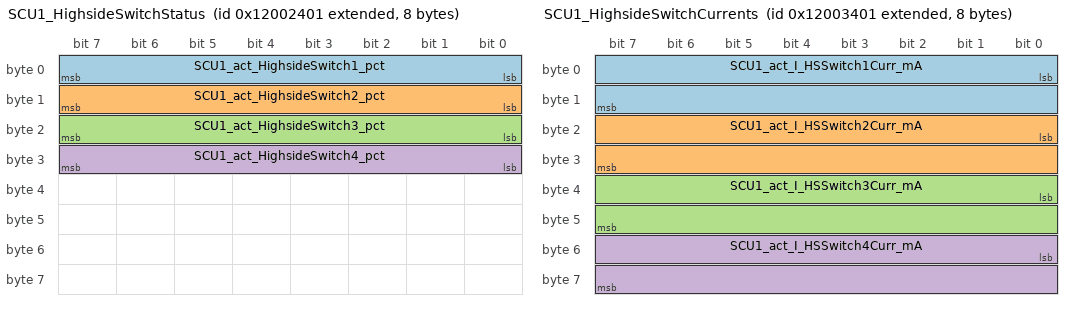
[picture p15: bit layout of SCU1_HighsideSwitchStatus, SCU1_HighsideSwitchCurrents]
BO_ 2449482753 SCU1_HighsideSwitchStatus: 8 Vector__XXX
SG_ SCU1_act_HighsideSwitch1_pct : 0|8@1+ (1,0) [0|255] "%" Vector__XXX
SG_ SCU1_act_HighsideSwitch2_pct : 8|8@1+ (1,0) [0|255] "%" Vector__XXX
SG_ SCU1_act_HighsideSwitch3_pct : 16|8@1+ (1,0) [0|255] "%" Vector__XXX
SG_ SCU1_act_HighsideSwitch4_pct : 24|8@1+ (1,0) [0|255] "%" Vector__XXX

BO_ 2449486849 SCU1_HighsideSwitchCurrents: 8 Vector__XXX
SG_ SCU1_act_I_HSSwitch1Curr_mA : 0|16@1+ (1,0) [0|65535] "mA" Vector__XXX
SG_ SCU1_act_I_HSSwitch2Curr_mA : 16|16@1+ (1,0) [0|65535] "mA" Vector__XXX
SG_ SCU1_act_I_HSSwitch3Curr_mA : 32|16@1+ (1,0) [0|65535] "mA" Vector__XXX
SG_ SCU1_act_I_HSSwitch4Curr_mA : 48|16@1+ (1,0) [0|65535] "mA" Vector__XXX

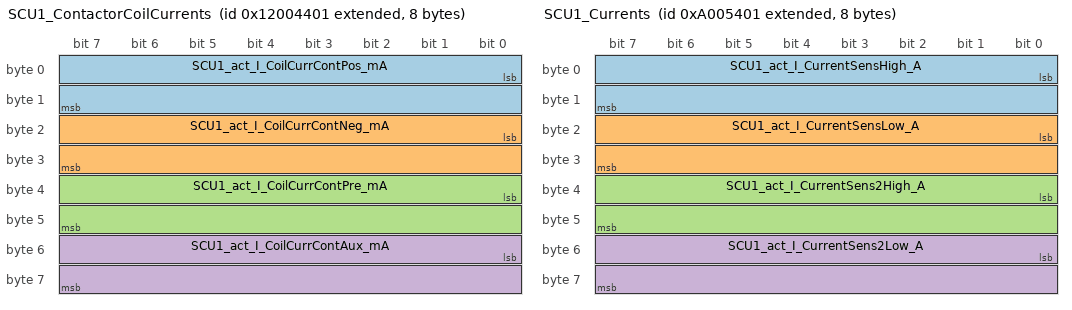
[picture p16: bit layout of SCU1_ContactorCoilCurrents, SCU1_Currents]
BO_ 2449490945 SCU1_ContactorCoilCurrents: 8 Vector__XXX
SG_ SCU1_act_I_CoilCurrContPos_mA : 0|16@1+ (1,0) [0|65535] "mA" Vector__XXX
SG_ SCU1_act_I_CoilCurrContNeg_mA : 16|16@1+ (1,0) [0|65535] "mA" Vector__XXX
SG_ SCU1_act_I_CoilCurrContPre_mA : 32|16@1+ (1,0) [0|65535] "mA" Vector__XXX
SG_ SCU1_act_I_CoilCurrContAux_mA : 48|16@1+ (1,0) [0|65535] "mA" Vector__XXX

BO_ 2315277313 SCU1_Currents: 8 Vector__XXX
SG_ SCU1_act_I_CurrentSensHigh_A : 0|16@1- (0.1,0) [-3276.8|3276.7] "A" Vector__XXX
SG_ SCU1_act_I_CurrentSensLow_A : 16|16@1- (0.1,0) [-3276.8|3276.7] "A" Vector__XXX
SG_ SCU1_act_I_CurrentSens2High_A : 32|16@1- (0.1,0) [-3276.8|3276.7] "A" Vector__XXX
SG_ SCU1_act_I_CurrentSens2Low_A : 48|16@1- (0.1,0) [-3276.8|3276.7] "A" Vector__XXX

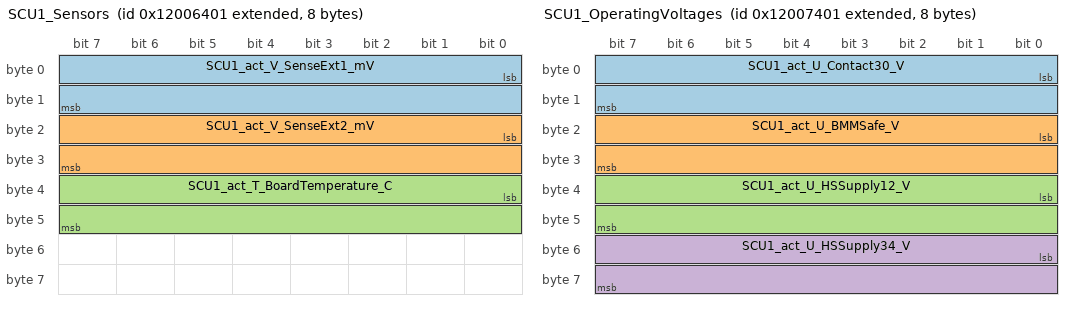
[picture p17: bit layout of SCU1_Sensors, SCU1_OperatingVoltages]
BO_ 2449499137 SCU1_Sensors: 8 Vector__XXX
SG_ SCU1_act_V_SenseExt1_mV : 0|16@1+ (1,0) [0|65535] "mV" Vector__XXX
SG_ SCU1_act_V_SenseExt2_mV : 16|16@1+ (1,0) [0|65535] "mV" Vector__XXX
SG_ SCU1_act_T_BoardTemperature_C : 32|16@1- (0.1,0) [-3276.8|3276.7] "°C" Vector__XXX

BO_ 2449503233 SCU1_OperatingVoltages: 8 Vector__XXX
SG_ SCU1_act_U_Contact30_V : 0|16@1+ (0.001,0) [0|65.535] "V" Vector__XXX
SG_ SCU1_act_U_BMMSafe_V : 16|16@1+ (0.001,0) [0|65.535] "V" Vector__XXX
SG_ SCU1_act_U_HSSupply12_V : 32|16@1+ (0.001,0) [0|65.535] "V" Vector__XXX
SG_ SCU1_act_U_HSSupply34_V : 48|16@1+ (0.001,0) [0|65.535] "V" Vector__XXX

BO_ 2315314177 SCU1_BatteryVoltagesPos: 8 Vector__XXX
SG_ SCU1_act_U_BatPos_V : 0|16@1- (0.1,0) [-3276.8|3276.7] "V" Vector__XXX
SG_ SCU1_act_U_SysPos_V : 16|16@1- (0.1,0) [-3276.8|3276.7] "V" Vector__XXX

BO_ 2315318273 SCU1_BatteryVoltagesNeg: 8 Vector__XXX
SG_ SCU1_act_U_BatNeg_V : 0|16@1- (0.1,0) [-3276.8|3276.7] "V" Vector__XXX
SG_ SCU1_act_U_SysNeg_V : 16|16@1- (0.1,0) [-3276.8|3276.7] "V" Vector__XXX

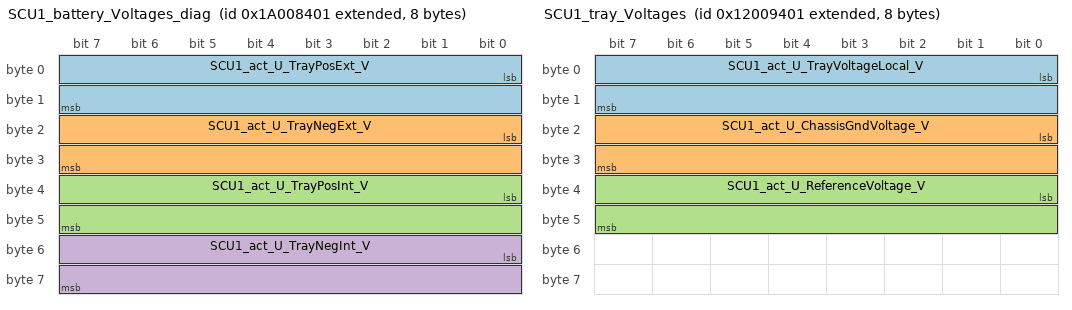
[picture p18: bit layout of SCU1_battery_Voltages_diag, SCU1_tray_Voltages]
BO_ 2583725057 SCU1_battery_Voltages_diag: 8 Vector__XXX
SG_ SCU1_act_U_TrayPosExt_V : 0|16@1- (0.1,0) [-3276.8|3276.7] "V" Vector__XXX
SG_ SCU1_act_U_TrayNegExt_V : 16|16@1- (0.1,0) [-3276.8|3276.7] "V" Vector__XXX
SG_ SCU1_act_U_TrayPosInt_V : 32|16@1- (0.1,0) [-3276.8|3276.7] "V" Vector__XXX
SG_ SCU1_act_U_TrayNegInt_V : 48|16@1- (0.1,0) [-3276.8|3276.7] "V" Vector__XXX

BO_ 2449511425 SCU1_tray_Voltages: 8 Vector__XXX
SG_ SCU1_act_U_TrayVoltageLocal_V : 0|16@1- (0.1,0) [-3276.8|3276.7] "V" Vector__XXX
SG_ SCU1_act_U_ChassisGndVoltage_V : 16|16@1+ (0.001,0) [0|65.535] "V" Vector__XXX
SG_ SCU1_act_U_ReferenceVoltage_V : 32|16@1+ (0.001,0) [0|65.535] "V" Vector__XXX

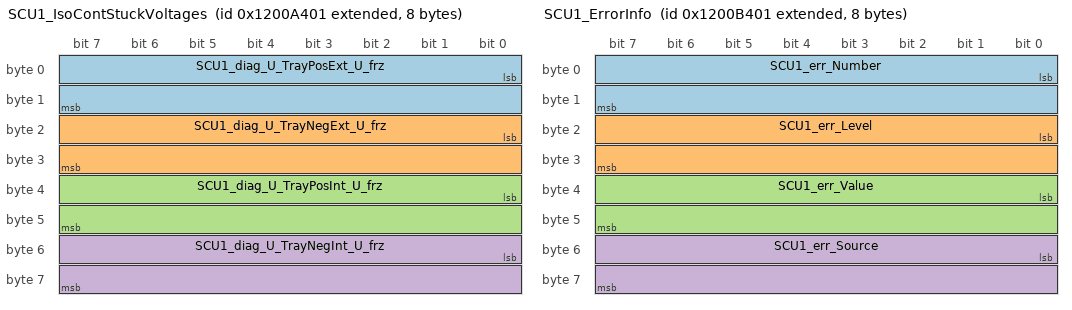
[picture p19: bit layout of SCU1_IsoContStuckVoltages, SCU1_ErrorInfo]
BO_ 2449515521 SCU1_IsoContStuckVoltages: 8 Vector__XXX
SG_ SCU1_diag_U_TrayPosExt_U_frz : 0|16@1- (0.1,0) [-3276.8|3276.7] "V" Vector__XXX
SG_ SCU1_diag_U_TrayNegExt_U_frz : 16|16@1- (0.1,0) [-3276.8|3276.7] "V" Vector__XXX
SG_ SCU1_diag_U_TrayPosInt_U_frz : 32|16@1- (0.1,0) [-3276.8|3276.7] "V" Vector__XXX
SG_ SCU1_diag_U_TrayNegInt_U_frz : 48|16@1- (0.1,0) [-3276.8|3276.7] "V" Vector__XXX

BO_ 2449519617 SCU1_ErrorInfo: 8 Vector__XXX
SG_ SCU1_err_Number : 0|16@1+ (1,0) [0|65535] "" Vector__XXX
SG_ SCU1_err_Level : 16|16@1+ (1,0) [0|65535] "" Vector__XXX
SG_ SCU1_err_Value : 32|16@1- (1,0) [-32768|32767] "" Vector__XXX
SG_ SCU1_err_Source : 48|16@1+ (1,0) [0|65535] "" Vector__XXX

BO_ 2449523713 SCU1_Warning: 8 Vector__XXX
SG_ SCU1_wf_CellVoltageMax : 0|1@1+ (1,0) [0|1] "" Vector__XXX
SG_ SCU1_wf_CellVoltageMin : 1|1@1+ (1,0) [0|1] "" Vector__XXX
SG_ SCU1_wf_SysVoltageMax : 2|1@1+ (1,0) [0|1] "" Vector__XXX
SG_ SCU1_wf_SysVoltageMin : 3|1@1+ (1,0) [0|1] "" Vector__XXX
SG_ SCU1_wf_SysVoltageSum : 4|1@1+ (1,0) [0|1] "" Vector__XXX
SG_ SCU1_wf_ModVoltageSum : 5|1@1+ (1,0) [0|1] "" Vector__XXX
SG_ SCU1_wf_ModVoltageRefMax : 6|1@1+ (1,0) [0|1] "" Vector__XXX
SG_ SCU1_wf_Mod_Voltage_Ref_Min : 7|1@1+ (1,0) [0|1] "" Vector__XXX
SG_ SCU1_wf_IsoFaultBattNeg : 8|1@1+ (1,0) [0|1] "" Vector__XXX
SG_ SCU1_wf_IsoFaultBattPos : 9|1@1+ (1,0) [0|1] "" Vector__XXX
SG_ SCU1_wf_ContactorNegStuck : 10|1@1+ (1,0) [0|1] "" Vector__XXX
SG_ SCU1_wf_ContactorPosStuck : 11|1@1+ (1,0) [0|1] "" Vector__XXX
SG_ SCU1_wf_LVSupplyMax : 12|1@1+ (1,0) [0|1] "" Vector__XXX
SG_ SCU1_wf_LVSupplyMin : 13|1@1+ (1,0) [0|1] "" Vector__XXX
SG_ SCU1_wf_TerminalTempMax : 14|1@1+ (1,0) [0|1] "" Vector__XXX
SG_ SCU1_wf_TerminalTempMin : 15|1@1+ (1,0) [0|1] "" Vector__XXX
SG_ SCU1_wf_CellTempChargMax : 16|1@1+ (1,0) [0|1] "" Vector__XXX
SG_ SCU1_wf_CellTempChargMin : 17|1@1+ (1,0) [0|1] "" Vector__XXX
SG_ SCU1_wf_CellTempDischMax : 18|1@1+ (1,0) [0|1] "" Vector__XXX
SG_ SCU1_wf_CellTempDischMin : 19|1@1+ (1,0) [0|1] "" Vector__XXX
SG_ SCU1_wf_SysCurCha : 20|1@1+ (1,0) [0|1] "" Vector__XXX
SG_ SCU1_wf_SysCurDis : 21|1@1+ (1,0) [0|1] "" Vector__XXX
SG_ SCU1_wf_HVCurrLoopMax : 22|1@1+ (1,0) [0|1] "" Vector__XXX
SG_ SCU1_wf_HVCurrLoopMin : 23|1@1+ (1,0) [0|1] "" Vector__XXX
SG_ SCU1_wf_eStopCurrLoopMax : 24|1@1+ (1,0) [0|1] "" Vector__XXX
SG_ SCU1_wf_eStopCurrLoopMin : 25|1@1+ (1,0) [0|1] "" Vector__XXX
SG_ SCU1_wf_SysCurLimitCha : 26|1@1+ (1,0) [0|1] "" Vector__XXX
SG_ SCU1_wf_SysCurLimitDis : 27|1@1+ (1,0) [0|1] "" Vector__XXX
SG_ SCU1_wf_SysPrechargeFailed : 28|1@1+ (1,0) [0|1] "" Vector__XXX
SG_ SCU1_wf_BMMBattCom : 29|1@1+ (1,0) [0|1] "" Vector__XXX
SG_ SCU1_wf_SysInitTimeout : 30|1@1+ (1,0) [0|1] "" Vector__XXX
SG_ SCU1_wf_SCUConfig : 31|1@1+ (1,0) [0|1] "" Vector__XXX
SG_ SCU1_wf_DeepDischProt : 32|1@1+ (1,0) [0|1] "" Vector__XXX
SG_ SCU1_wf_WDReset : 33|1@1+ (1,0) [0|1] "" Vector__XXX
SG_ SCU1_wf_ExtCommunicationTout : 34|1@1+ (1,0) [0|1] "" Vector__XXX
SG_ SCU1_wf_NoAfterrunTest : 35|1@1+ (1,0) [0|1] "" Vector__XXX
SG_ SCU1_wf_CellVoltUnbalance : 36|1@1+ (1,0) [0|1] "" Vector__XXX
SG_ SCU1_wf_CellTempUnbalance : 37|1@1+ (1,0) [0|1] "" Vector__XXX
SG_ SCU1_wf_TerminalTempUnbalance : 38|1@1+ (1,0) [0|1] "" Vector__XXX
SG_ SCU1_wf_LTCError : 39|1@1+ (1,0) [0|1] "" Vector__XXX
SG_ SCU1_wf_AfterrunTest : 40|1@1+ (1,0) [0|1] "" Vector__XXX
SG_ SCU1_wf_CrossCheck : 41|1@1+ (1,0) [0|1] "" Vector__XXX
SG_ SCU1_wf_StuckAtTemp : 42|1@1+ (1,0) [0|1] "" Vector__XXX
SG_ SCU1_wf_StuckAtVolt : 43|1@1+ (1,0) [0|1] "" Vector__XXX
SG_ SCU1_wf_ProgProcess : 44|1@1+ (1,0) [0|1] "" Vector__XXX
SG_ SCU1_wf_RAM : 45|1@1+ (1,0) [0|1] "" Vector__XXX
SG_ SCU1_wf_ROM : 46|1@1+ (1,0) [0|1] "" Vector__XXX
SG_ SCU1_wf_FlashEEPROM : 47|1@1+ (1,0) [0|1] "" Vector__XXX
SG_ SCU1_wf_InvalidData : 48|1@1+ (1,0) [0|1] "" Vector__XXX
SG_ SCU1_wf_ContactorWrongState : 49|1@1+ (1,0) [0|1] "" Vector__XXX
SG_ SCU1_wf_CurrSens : 50|1@1+ (1,0) [0|1] "" Vector__XXX
SG_ SCU1_wf_ContDam : 51|1@1+ (1,0) [0|1] "" Vector__XXX
SG_ SCU1_wf_RefVoltErrorMax : 52|1@1+ (1,0) [0|1] "" Vector__XXX
SG_ SCU1_wf_RefVoltErrorMin : 53|1@1+ (1,0) [0|1] "" Vector__XXX
SG_ SCU1_wf_KL30SafeMax : 54|1@1+ (1,0) [0|1] "" Vector__XXX
SG_ SCU1_wf_KL30SafeMin : 55|1@1+ (1,0) [0|1] "" Vector__XXX
SG_ SCU1_wf_CPUSupplyWarning : 56|1@1+ (1,0) [0|1] "" Vector__XXX
SG_ SCU1_wf_PowerProtectionWarning : 57|1@1+ (1,0) [0|1] "" Vector__XXX
SG_ SCU1_wf_KL30SafeOff : 58|1@1+ (1,0) [0|1] "" Vector__XXX
SG_ SCU1_wf_Dew_Sensor : 59|1@1+ (1,0) [0|1] "" Vector__XXX
SG_ SCU1_wf_ContactorDropOut : 60|1@1+ (1,0) [0|1] "" Vector__XXX
SG_ SCU1_wf_BoardTemp : 61|1@1+ (1,0) [0|1] "" Vector__XXX
SG_ SCU1_wf_SCUError : 63|1@1+ (1,0) [0|1] "" Vector__XXX

CM_ BO_ 2416478208 "Starts action for all modules in daisy-chain (Starts action for all modules in daisy-chain)";
CM_ SG_ 2416478208 M001_LockIDPageCommand "Lock ID Page Command";
CM_ BO_ 2415922177 "Information about cell voltages an temperature (Information about cell voltages an temperature)";
CM_ SG_ 2415922177 V001_act_U_CellVoltage_mV "active cell voltage";
CM_ SG_ 2415922177 T001_act_T_CellTemp_C "active cell temperature";
CM_ SG_ 2415922177 V001_act_U_GPIOVoltage_mV "only EOL: GPIO voltage to corresponding cell temperature";
CM_ SG_ 2415922177 B001_flag_Balancing "shows if Balancing for the Cell is active";
CM_ BO_ 2415922178 "Information about cell voltages an temperature (Information about cell voltages an temperature)";
CM_ SG_ 2415922178 V002_act_U_CellVoltage_mV "active cell voltage";
CM_ SG_ 2415922178 T002_act_T_CellTemp_C "active cell temperature";
CM_ SG_ 2415922178 V002_act_U_GPIOVoltage_mV "only EOL: GPIO voltage to corresponding cell temperature";
CM_ SG_ 2415922178 B002_flag_Balancing "shows if Balancing for the Cell is active";
CM_ BO_ 2415922179 "Information about cell voltages an temperature (Information about cell voltages an temperature)";
CM_ SG_ 2415922179 V003_act_U_CellVoltage_mV "active cell voltage";
CM_ SG_ 2415922179 T003_act_T_CellTemp_C "active cell temperature";
CM_ SG_ 2415922179 V003_act_U_GPIOVoltage_mV "only EOL: GPIO voltage to corresponding cell temperature";
CM_ SG_ 2415922179 B003_flag_Balancing "shows if Balancing for the Cell is active";
CM_ BO_ 2415922180 "Information about cell voltages an temperature (Information about cell voltages an temperature)";
CM_ SG_ 2415922180 V004_act_U_CellVoltage_mV "active cell voltage";
CM_ SG_ 2415922180 T004_act_T_CellTemp_C "active cell temperature";
CM_ SG_ 2415922180 V004_act_U_GPIOVoltage_mV "only EOL: GPIO voltage to corresponding cell temperature";
CM_ SG_ 2415922180 B004_flag_Balancing "shows if Balancing for the Cell is active";
CM_ BO_ 2415922181 "Information about cell voltages an temperature (Information about cell voltages an temperature)";
CM_ SG_ 2415922181 V005_act_U_CellVoltage_mV "active cell voltage";
CM_ SG_ 2415922181 T005_act_T_CellTemp_C "active cell temperature";
CM_ SG_ 2415922181 V005_act_U_GPIOVoltage_mV "only EOL: GPIO voltage to corresponding cell temperature";
CM_ SG_ 2415922181 B005_flag_Balancing "shows if Balancing for the Cell is active";
CM_ BO_ 2415922182 "Information about cell voltages an temperature (Information about cell voltages an temperature)";
CM_ SG_ 2415922182 V006_act_U_CellVoltage_mV "active cell voltage";
CM_ SG_ 2415922182 T006_act_T_CellTemp_C "active cell temperature";
CM_ SG_ 2415922182 V006_act_U_GPIOVoltage_mV "only EOL: GPIO voltage to corresponding cell temperature";
CM_ SG_ 2415922182 B006_flag_Balancing "shows if Balancing for the Cell is active";
CM_ BO_ 2415922183 "Information about cell voltages an temperature (Information about cell voltages an temperature)";
CM_ SG_ 2415922183 V007_act_U_CellVoltage_mV "active cell voltage";
CM_ SG_ 2415922183 T007_act_T_CellTemp_C "active cell temperature";
CM_ SG_ 2415922183 V007_act_U_GPIOVoltage_mV "only EOL: GPIO voltage to corresponding cell temperature";
CM_ SG_ 2415922183 B007_flag_Balancing "shows if Balancing for the Cell is active";
CM_ BO_ 2415922184 "Information about cell voltages an temperature (Information about cell voltages an temperature)";
CM_ SG_ 2415922184 V008_act_U_CellVoltage_mV "active cell voltage";
CM_ SG_ 2415922184 T008_act_T_CellTemp_C "active cell temperature";
CM_ SG_ 2415922184 V008_act_U_GPIOVoltage_mV "only EOL: GPIO voltage to corresponding cell temperature";
CM_ SG_ 2415922184 B008_flag_Balancing "shows if Balancing for the Cell is active";
CM_ BO_ 2415922185 "Information about cell voltages an temperature (Information about cell voltages an temperature)";
CM_ SG_ 2415922185 V009_act_U_CellVoltage_mV "active cell voltage";
CM_ SG_ 2415922185 T009_act_T_CellTemp_C "active cell temperature";
CM_ SG_ 2415922185 V009_act_U_GPIOVoltage_mV "only EOL: GPIO voltage to corresponding cell temperature";
CM_ SG_ 2415922185 B009_flag_Balancing "shows if Balancing for the Cell is active";
CM_ BO_ 2415922186 "Information about cell voltages an temperature (Information about cell voltages an temperature)";
CM_ SG_ 2415922186 V010_act_U_CellVoltage_mV "active cell voltage";
CM_ SG_ 2415922186 T010_act_T_CellTemp_C "active cell temperature";
CM_ SG_ 2415922186 V010_act_U_GPIOVoltage_mV "only EOL: GPIO voltage to corresponding cell temperature";
CM_ SG_ 2415922186 B010_flag_Balancing "shows if Balancing for the Cell is active";
CM_ BO_ 2415922187 "Information about cell voltages an temperature (Information about cell voltages an temperature)";
CM_ SG_ 2415922187 V011_act_U_CellVoltage_mV "active cell voltage";
CM_ SG_ 2415922187 T011_act_T_CellTemp_C "active cell temperature";
CM_ SG_ 2415922187 V011_act_U_GPIOVoltage_mV "only EOL: GPIO voltage to corresponding cell temperature";
CM_ SG_ 2415922187 B011_flag_Balancing "shows if Balancing for the Cell is active";
CM_ BO_ 2415922188 "Information about cell voltages an temperature (Information about cell voltages an temperature)";
CM_ SG_ 2415922188 V012_act_U_CellVoltage_mV "active cell voltage";
CM_ SG_ 2415922188 T012_act_T_CellTemp_C "active cell temperature";
CM_ SG_ 2415922188 V012_act_U_GPIOVoltage_mV "only EOL: GPIO voltage to corresponding cell temperature";
CM_ SG_ 2415922188 B012_flag_Balancing "shows if Balancing for the Cell is active";
CM_ BO_ 2415922189 "Information about cell voltages an temperature (Information about cell voltages an temperature)";
CM_ SG_ 2415922189 V013_act_U_CellVoltage_mV "active cell voltage";
CM_ SG_ 2415922189 T013_act_T_CellTemp_C "active cell temperature";
CM_ SG_ 2415922189 V013_act_U_GPIOVoltage_mV "only EOL: GPIO voltage to corresponding cell temperature";
CM_ SG_ 2415922189 B013_flag_Balancing "shows if Balancing for the Cell is active";
CM_ BO_ 2415922190 "Information about cell voltages an temperature (Information about cell voltages an temperature)";
CM_ SG_ 2415922190 V014_act_U_CellVoltage_mV "active cell voltage";
CM_ SG_ 2415922190 T014_act_T_CellTemp_C "active cell temperature";
CM_ SG_ 2415922190 V014_act_U_GPIOVoltage_mV "only EOL: GPIO voltage to corresponding cell temperature";
CM_ SG_ 2415922190 B014_flag_Balancing "shows if Balancing for the Cell is active";
CM_ BO_ 2415922191 "Information about cell voltages an temperature (Information about cell voltages an temperature)";
CM_ SG_ 2415922191 V015_act_U_CellVoltage_mV "active cell voltage";
CM_ SG_ 2415922191 T015_act_T_CellTemp_C "active cell temperature";
CM_ SG_ 2415922191 V015_act_U_GPIOVoltage_mV "only EOL: GPIO voltage to corresponding cell temperature";
CM_ SG_ 2415922191 B015_flag_Balancing "shows if Balancing for the Cell is active";
CM_ BO_ 2415922192 "Information about cell voltages an temperature (Information about cell voltages an temperature)";
CM_ SG_ 2415922192 V016_act_U_CellVoltage_mV "active cell voltage";
CM_ SG_ 2415922192 T016_act_T_CellTemp_C "active cell temperature";
CM_ SG_ 2415922192 V016_act_U_GPIOVoltage_mV "only EOL: GPIO voltage to corresponding cell temperature";
CM_ SG_ 2415922192 B016_flag_Balancing "shows if Balancing for the Cell is active";
CM_ BO_ 2415922193 "Information about cell voltages an temperature (Information about cell voltages an temperature)";
CM_ SG_ 2415922193 V017_act_U_CellVoltage_mV "active cell voltage";
CM_ SG_ 2415922193 T017_act_T_CellTemp_C "active cell temperature";
CM_ SG_ 2415922193 V017_act_U_GPIOVoltage_mV "only EOL: GPIO voltage to corresponding cell temperature";
CM_ SG_ 2415922193 B017_flag_Balancing "shows if Balancing for the Cell is active";
CM_ BO_ 2415922194 "Information about cell voltages an temperature (Information about cell voltages an temperature)";
CM_ SG_ 2415922194 V018_act_U_CellVoltage_mV "active cell voltage";
CM_ SG_ 2415922194 T018_act_T_CellTemp_C "active cell temperature";
CM_ SG_ 2415922194 V018_act_U_GPIOVoltage_mV "only EOL: GPIO voltage to corresponding cell temperature";
CM_ SG_ 2415922194 B018_flag_Balancing "shows if Balancing for the Cell is active";
CM_ BO_ 2415922195 "Information about cell voltages an temperature (Information about cell voltages an temperature)";
CM_ SG_ 2415922195 V019_act_U_CellVoltage_mV "active cell voltage";
CM_ SG_ 2415922195 T019_act_T_CellTemp_C "active cell temperature";
CM_ SG_ 2415922195 V019_act_U_GPIOVoltage_mV "only EOL: GPIO voltage to corresponding cell temperature";
CM_ SG_ 2415922195 B019_flag_Balancing "shows if Balancing for the Cell is active";
CM_ BO_ 2415922196 "Information about cell voltages an temperature (Information about cell voltages an temperature)";
CM_ SG_ 2415922196 V020_act_U_CellVoltage_mV "active cell voltage";
CM_ SG_ 2415922196 T020_act_T_CellTemp_C "active cell temperature";
CM_ SG_ 2415922196 V020_act_U_GPIOVoltage_mV "only EOL: GPIO voltage to corresponding cell temperature";
CM_ SG_ 2415922196 B020_flag_Balancing "shows if Balancing for the Cell is active";
CM_ BO_ 2415925249 "Information about temperatures on module terminals (Information about temperatures on module terminals)";
CM_ SG_ 2415925249 M001_raw_DewSens "raw value of Dew Sensor ADC (optional)";
CM_ SG_ 2415925249 M001_act_T_TermTempNeg_C "temperature measured on negative terminal";
CM_ SG_ 2415925249 M001_act_T_TermTempPos_C "temperature measured on positive terminal";
CM_ BO_ 2415929345 "information about module voltages and split temperatures (information about module voltages and split temperatures)";
CM_ SG_ 2415929345 M001_act_T_TermTempSplitNeg "temperature measured on negative split terminal";
CM_ SG_ 2415929345 M001_act_T_TermTempSplitPos "temperature measured on positive split terminal";
CM_ SG_ 2415929345 M001_act_U_ModuleVoltage_V "measured module voltage";
CM_ BO_ 2415937537 "module configuration information (module configuration information)";
CM_ SG_ 2415937537 M001_inf_SerialCells "Number of Cells in series";
CM_ SG_ 2415937537 M001_inf_ParallelCells "Number of parallel Cells";
CM_ SG_ 2415937537 M001_inf_CellTypeMajor "used Cell Type (Type)";
CM_ SG_ 2415937537 M001_inf_CellTypeMinor "used Cell Type (Index/revision)";
CM_ BO_ 2415941633 "module version and Error information (module version and Error information)";
CM_ SG_ 2415941633 M001_flag_CalibrationDone "shows if module is calibrated";
CM_ SG_ 2415941633 M001_flag_CalibrationIncomp "shows if calibration data is missing";
CM_ SG_ 2415941633 M001_flag_CalibrationError "shows if there was an error while calibrating or calibration data is out of limits";
CM_ SG_ 2415941633 M001_flag_EEPROMError "shows if there was an error while reading/writig to EEPROM";
CM_ SG_ 2415941633 M001_flag_WDGError "shows if Watchdog has been triggered";
CM_ SG_ 2415941633 M001_flag_ConfigDone "shows if serial number has been set and topology has been set and locked";
CM_ SG_ 2415941633 M001_flag_TempCalErr "shows if there has been an error with the temperature calibration";
CM_ SG_ 2415941633 M001_flag_SerialMiss "shows if module serial number has not been set";
CM_ SG_ 2415941633 M001_flag_ThermalShtDwn_IC1 "shows if IC 1 has a temperature over 125 °C";
CM_ SG_ 2415941633 M001_flag_ThermalShtDwn_IC2 "shows if IC 2 has a temperature over 125 °C";
CM_ SG_ 2415941633 M001_flag_ThermalShtDwn_IC3 "shows if IC 3 has a temperature over 125 °C";
CM_ SG_ 2415941633 M001_flag_ThermalShtDwn_IC4 "shows if IC 4 has a temperature over 125 °C";
CM_ SG_ 2415941633 M001_flag_SelfTestPassed "shows if all self-tests have been passed";
CM_ SG_ 2415941633 M001_flag_SM_PollTimeout "isoSPI ADC polling timeout or too many ICs connected during execution of any safety mechanism";
CM_ SG_ 2415941633 M001_flag_NoSafRel_PollTimeout "isoSPI ADC polling timeout or too many ICs connected during execution of any not safety relevant command";
CM_ SG_ 2415941633 M001_flag_SM_BadCRC_IC1 "isoSPI communication error during execution of any safety mechanism";
CM_ SG_ 2415941633 M001_flag_SM_BadCRC_IC2 "isoSPI communication error during execution of any safety mechanism";
CM_ SG_ 2415941633 M001_flag_SM_BadCRC_IC3 "isoSPI communication error during execution of any safety mechanism";
CM_ SG_ 2415941633 M001_flag_SM_BadCRC_IC4 "isoSPI communication error during execution of any safety mechanism";
CM_ SG_ 2415941633 M001_flag_NoSafRel_BadCRC_IC1 "isoSPI communication error during execution any not safety relevant command";
CM_ SG_ 2415941633 M001_flag_NoSafRel_BadCRC_IC2 "isoSPI communication error during execution any not safety relevant command";
CM_ SG_ 2415941633 M001_flag_NoSafRel_BadCRC_IC3 "isoSPI communication error during execution any not safety relevant command";
CM_ SG_ 2415941633 M001_flag_NoSafRel_BadCRC_IC4 "isoSPI communication error during execution any not safety relevant command";
CM_ SG_ 2415941633 M001_flag_BadCRC_IC1 "isoSPI communication error";
CM_ SG_ 2415941633 M001_flag_BadCRC_IC2 "isoSPI communication error";
CM_ SG_ 2415941633 M001_flag_BadCRC_IC3 "isoSPI communication error";
CM_ SG_ 2415941633 M001_flag_BadCRC_IC4 "isoSPI communication error";
CM_ SG_ 2415941633 M001_flag_PollTimeout "isoSPI ADC polling timeout or too many ICs connected";
CM_ SG_ 2415941633 M001_flag_ComplSafAreaCRCErr "both EEPROM safety areas contain a bad CRC";
CM_ SG_ 2415941633 M001_flag_ComplStatAreaCRCErr "both EEPROM static areas contain a bad CRC";
CM_ SG_ 2415941633 M001_flag_ComplDynAreaCRCErr "both EEPROM dynamic areas contain a bad CRC";
CM_ SG_ 2415941633 M001_flag_InitialisationFail "isoSPI module in BMU was not initalised successfully";
CM_ SG_ 2415941633 M001_flag_SingleSafAreaCRCErr "one of EEPROM safety areas is corrupted";
CM_ SG_ 2415941633 M001_flag_SingleStatAreaCRCErr "one of EEPROM static areas is corrupted";
CM_ SG_ 2415941633 M001_flag_SingleDynAreaCRCErr "one of EEPROM dynamic areas is corrupted";
CM_ SG_ 2415941633 M001_flag_SafAreaMismatch "CRC of both EEPROM safety areas is correct, but content doesn't match";
CM_ SG_ 2415941633 M001_flag_StatAreaMismatch "CRC of both EEPROM static areas is correct, but content doesn't match";
CM_ SG_ 2415941633 M001_flag_IDPageNotLocked "EEPROM ID page is not locked";
CM_ SG_ 2415941633 M001_flag_I2CCommunicationFail "I2C communication error";
CM_ SG_ 2415941633 M001_flag_EEPROMReadFail "reading all EEPROM content failed";
CM_ SG_ 2415941633 M001_flag_IDPageStatusReadFail "reading EEPROM ID page status failed";
CM_ SG_ 2415941633 M001_flag_SafAreaWriteFail "writing EEPROM safety area failed";
CM_ SG_ 2415941633 M001_flag_StatreaWriteFail "writing EEPROM static area failed";
CM_ SG_ 2415941633 M001_flag_DynAreaWriteFail "writing EEPROM dynamic area failed";
CM_ SG_ 2415941633 M001_flag_SafAreaReadFail "reading EEPROM safety area failed";
CM_ SG_ 2415941633 M001_flag_StatAreaReadFail "reading EEPROM static area failed";
CM_ SG_ 2415941633 M001_flag_DynAreaReadFail "reading EEPROM dynamic area failed";
CM_ SG_ 2415941633 M001_flag_VerifySafWriteFail "writing EEPROM safety area was not successful";
CM_ SG_ 2415941633 M001_flag_VerifyStatWriteFail "writing EEPROM static area was not successful";
CM_ SG_ 2415941633 M001_flag_VerifyDynWriteFail "writing EEPROM dynamic area was not successful";
CM_ BO_ 2415986689 "Safety Mechanism Flags (Safety Mechanism Flags)";
CM_ SG_ 2415986689 M001_OpenWireDetectedCV_IC1 "open cell wire(s) detected at IC1";
CM_ SG_ 2415986689 M001_ADCOverlapTestFailed_IC1 "ADC overlap test failed for IC1";
CM_ SG_ 2415986689 M001_ADCSefttestCVFailed_IC1 "ADC & memory test of cell voltages failed for IC1";
CM_ SG_ 2415986689 M001_ADCSefttestAUXFailed_IC1 "ADC & memory test of GPIO voltages failed for IC1";
CM_ SG_ 2415986689 M001_OpenWireDetectedAUX_IC1 "open GPIO wire(s) detected at IC1";
CM_ SG_ 2415986689 M001_MUXFail_IC1 "MUX test failed for IC1";
CM_ SG_ 2415986689 M001_BadCRCAccepted_IC1 "LTC (IC1) accepted a bad CRC";
CM_ SG_ 2415986689 M001_GPIOAdjShortDetected_IC1 "GPIO adjacent short detected at IC1";
CM_ SG_ 2415986689 M001_CLRCmdBroken_IC1 "LTC (IC1) clear command is broken";
CM_ SG_ 2415986689 M001_WrongPathSelection_IC1 "wrong path selection for IC1";
CM_ SG_ 2415986689 M001_OWCircuitStuckCV_IC1 "open cell wire circuit stuck for IC1";
CM_ SG_ 2415986689 M001_DischargeCircuitFault_IC1 "fault in discharge circuit at IC1";
CM_ SG_ 2415986689 M001_SM_digRedFail_IC1 "digital redundancy fail detected during execution of any safety mechanism at IC1";
CM_ SG_ 2415986689 M001_SM_ClrRegsFail_IC1 "registers were not cleared during execution of any safety mechanisms at IC1";
CM_ SG_ 2415986689 M001_OpenWireDetectedCV_IC2 "open cell wire(s) detected at IC2";
CM_ SG_ 2415986689 M001_ADCOverlapTestFailed_IC2 "ADC overlap test failed for IC2";
CM_ SG_ 2415986689 M001_ADCSefttestCVFailed_IC2 "ADC & memory test of cell voltages failed for IC2";
CM_ SG_ 2415986689 M001_ADCSefttestAUXFailed_IC2 "ADC & memory test of GPIO voltages failed for IC2";
CM_ SG_ 2415986689 M001_OpenWireDetectedAUX_IC2 "open GPIO wire(s) detected at IC2";
CM_ SG_ 2415986689 M001_MUXFail_IC2 "MUX test failed for IC2";
CM_ SG_ 2415986689 M001_BadCRCAccepted_IC2 "LTC (IC2) accepted a bad CRC";
CM_ SG_ 2415986689 M001_GPIOAdjShortDetected_IC2 "GPIO adjacent short detected at IC2";
CM_ SG_ 2415986689 M001_CLRCmdBroken_IC2 "LTC (IC2) clear command is broken";
CM_ SG_ 2415986689 M001_WrongPathSelection_IC2 "wrong path selection for IC2";
CM_ SG_ 2415986689 M001_OWCircuitStuckCV_IC2 "open cell wire circuit stuck for IC2";
CM_ SG_ 2415986689 M001_DischargeCircuitFault_IC2 "fault in discharge circuit at IC2";
CM_ SG_ 2415986689 M001_SM_digRedFail_IC2 "digital redundancy fail detected during execution of any safety mechanism at IC2";
CM_ SG_ 2415986689 M001_SM_ClrRegsFail_IC2 "registers were not cleared during execution of any safety mechanisms at IC2";
CM_ SG_ 2415986689 M001_OpenWireDetectedCV_IC3 "open cell wire(s) detected at IC3";
CM_ SG_ 2415986689 M001_ADCOverlapTestFailed_IC3 "ADC overlap test failed for IC3";
CM_ SG_ 2415986689 M001_ADCSefttestCVFailed_IC3 "ADC & memory test of cell voltages failed for IC3";
CM_ SG_ 2415986689 M001_ADCSefttestAUXFailed_IC3 "ADC & memory test of GPIO voltages failed for IC3";
CM_ SG_ 2415986689 M001_OpenWireDetectedAUX_IC3 "open GPIO wire(s) detected at IC3";
CM_ SG_ 2415986689 M001_MUXFail_IC3 "MUX test failed for IC3";
CM_ SG_ 2415986689 M001_BadCRCAccepted_IC3 "LTC (IC3) accepted a bad CRC";
CM_ SG_ 2415986689 M001_GPIOAdjShortDetected_IC3 "GPIO adjacent short detected at IC3";
CM_ SG_ 2415986689 M001_CLRCmdBroken_IC3 "LTC (IC3) clear command is broken";
CM_ SG_ 2415986689 M001_WrongPathSelection_IC3 "wrong path selection for IC3";
CM_ SG_ 2415986689 M001_OWCircuitStuckCV_IC3 "open cell wire circuit stuck for IC3";
CM_ SG_ 2415986689 M001_DischargeCircuitFault_IC3 "fault in discharge circuit at IC3";
CM_ SG_ 2415986689 M001_SM_digRedFail_IC3 "digital redundancy fail detected during execution of any safety mechanism at IC3";
CM_ SG_ 2415986689 M001_SM_ClrRegsFail_IC3 "registers were not cleared during execution of any safety mechanisms at IC3";
CM_ SG_ 2415986689 M001_OpenWireDetectedCV_IC4 "open cell wire(s) detected at IC4";
CM_ SG_ 2415986689 M001_ADCOverlapTestFailed_IC4 "ADC overlap test failed for IC4";
CM_ SG_ 2415986689 M001_ADCSefttestCVFailed_IC4 "ADC & memory test of cell voltages failed for IC4";
CM_ SG_ 2415986689 M001_ADCSefttestAUXFailed_IC4 "ADC & memory test of GPIO voltages failed for IC4";
CM_ SG_ 2415986689 M001_OpenWireDetectedAUX_IC4 "open GPIO wire(s) detected at IC4";
CM_ SG_ 2415986689 M001_MUXFail_IC4 "MUX test failed for IC4";
CM_ SG_ 2415986689 M001_BadCRCAccepted_IC4 "LTC (IC4) accepted a bad CRC";
CM_ SG_ 2415986689 M001_GPIOAdjShortDetected_IC4 "GPIO adjacent short detected at IC4";
CM_ SG_ 2415986689 M001_CLRCmdBroken_IC4 "LTC (IC4) clear command is broken";
CM_ SG_ 2415986689 M001_WrongPathSelection_IC4 "wrong path selection for IC4";
CM_ SG_ 2415986689 M001_OWCircuitStuckCV_IC4 "open cell wire circuit stuck for IC4";
CM_ SG_ 2415986689 M001_DischargeCircuitFault_IC4 "fault in discharge circuit at IC4";
CM_ SG_ 2415986689 M001_SM_digRedFail_IC4 "digital redundancy fail detected during execution of any safety mechanism at IC4";
CM_ SG_ 2415986689 M001_SM_ClrRegsFail_IC4 "registers were not cleared during execution of any safety mechanisms at IC4";
CM_ BO_ 2415933441 "information about module voltages (information about module voltages)";
CM_ SG_ 2415933441 M001_min_U_CellVoltage_mV_fast "lowest cell voltage in module";
CM_ SG_ 2415933441 M001_max_U_CellVoltage_mV_fast "highest cell voltage in module";
CM_ SG_ 2415933441 M001_avg_U_CellVoltage_mV_fast "average cell voltage in module";
CM_ BO_ 2550712321 "information for module calibration (information for module calibration)";
CM_ SG_ 2550712321 M001_conf_IdxOfTempSensor "Index of temperature sensor";
CM_ SG_ 2550712321 M001_conf_RefTemperature_C "calibration reference temperature";
CM_ SG_ 2550712321 M001_conf_A_CurrentOffsetA_mA "calibration current offset A";
CM_ SG_ 2550712321 M001_conf_A_CurrentOffsetB_mA "calibration current offset B";
CM_ SG_ 2550712321 M001_conf_A_CurrentFactorA_mA "calibration current factor A";
CM_ SG_ 2550712321 M001_conf_A_CurrentFactorB_mA "calibration current factor B";
CM_ SG_ 2550712321 M001_conf_U_VoltageIC1_mV "calibration voltage IC1";
CM_ SG_ 2550712321 M001_conf_U_VoltageIC2_mV "calibration voltage IC2";
CM_ SG_ 2550712321 M001_conf_U_VoltageIC3_mV "calibration voltage IC3";
CM_ SG_ 2550712321 M001_conf_U_VoltageIC4_mV "calibration voltage IC4";
CM_ BO_ 2550716417 "information for module configuration (information for module configuration)";
CM_ SG_ 2550716417 M001_conf_NewSerialNrLo "new serial number lower part";
CM_ SG_ 2550716417 M001_conf_NewSerialNrHi "new serial number higher part";
CM_ SG_ 2550716417 M001_conf_PCBNewSerialNrLo "PCB new serial number lower part";
CM_ SG_ 2550716417 M001_conf_PCBNewSerialNrHi "PCB new serial number higher part";
CM_ SG_ 2550716417 M001_conf_NewModuleTypeMajor "new module type (Type)";
CM_ SG_ 2550716417 M001_conf_NewModuleTypeMinor "new module type (Index/revision)";
CM_ SG_ 2550716417 M001_conf_NewPCBTypeMajor "new PCB type (Type)";
CM_ SG_ 2550716417 M001_conf_NewPCBTypeMinor "new PCB type (Index/revision)";
CM_ SG_ 2550716417 M001_conf_NewICTypeMajor "new IC type (Type)";
CM_ SG_ 2550716417 M001_conf_NewICTypeMinor "new IC type (Index/revision)";
CM_ SG_ 2550716417 M001_conf_NewCellTypeMajor "new Cell type (Type)";
CM_ SG_ 2550716417 M001_conf_NewCellTypeMinor "new Cell type (Index/revision)";
CM_ SG_ 2550716417 M001_conf_TopologyMajor "Number of cells in serial";
CM_ SG_ 2550716417 M001_conf_TopologyMinor "Number of parallel cells";
CM_ BO_ 2451052545 "commands module to balance cells (commands module to balance cells)";
CM_ SG_ 2451052545 M001_flag_BalanceCell1 "commands module to balance cell 1";
CM_ SG_ 2451052545 M001_flag_BalanceCell2 "commands module to balance cell 2";
CM_ SG_ 2451052545 M001_flag_BalanceCell3 "commands module to balance cell 3";
CM_ SG_ 2451052545 M001_flag_BalanceCell4 "commands module to balance cell 4";
CM_ SG_ 2451052545 M001_flag_BalanceCell5 "commands module to balance cell 5";
CM_ SG_ 2451052545 M001_flag_BalanceCell6 "commands module to balance cell 6";
CM_ SG_ 2451052545 M001_flag_BalanceCell7 "commands module to balance cell 7";
CM_ SG_ 2451052545 M001_flag_BalanceCell8 "commands module to balance cell 8";
CM_ SG_ 2451052545 M001_flag_BalanceCell9 "commands module to balance cell 9";
CM_ SG_ 2451052545 M001_flag_BalanceCell10 "commands module to balance cell 10";
CM_ SG_ 2451052545 M001_flag_BalanceCell11 "commands module to balance cell 11";
CM_ SG_ 2451052545 M001_flag_BalanceCell12 "commands module to balance cell 12";
CM_ SG_ 2451052545 M001_flag_BalanceCell13 "commands module to balance cell 13";
CM_ SG_ 2451052545 M001_flag_BalanceCell14 "commands module to balance cell 14";
CM_ SG_ 2451052545 M001_flag_BalanceCell15 "commands module to balance cell 15";
CM_ SG_ 2451052545 M001_flag_BalanceCell16 "commands module to balance cell 16";
CM_ SG_ 2451052545 M001_flag_BalanceCell17 "commands module to balance cell 17";
CM_ SG_ 2451052545 M001_flag_BalanceCell18 "commands module to balance cell 18";
CM_ SG_ 2451052545 M001_flag_BalanceCell19 "commands module to balance cell 19";
CM_ SG_ 2451052545 M001_flag_BalanceCell20 "commands module to balance cell 20";
CM_ SG_ 2451052545 M001_flag_BalanceCell21 "commands module to balance cell 21";
CM_ SG_ 2451052545 M001_flag_BalanceCell22 "commands module to balance cell 22";
CM_ SG_ 2451052545 M001_flag_BalanceCell23 "commands module to balance cell 23";
CM_ SG_ 2451052545 M001_flag_BalanceCell24 "commands module to balance cell 24";
CM_ SG_ 2451052545 M001_flag_BalanceCell25 "commands module to balance cell 25";
CM_ SG_ 2451052545 M001_flag_BalanceCell26 "commands module to balance cell 26";
CM_ SG_ 2451052545 M001_flag_BalanceCell27 "commands module to balance cell 27";
CM_ SG_ 2451052545 M001_flag_BalanceCell28 "commands module to balance cell 28";
CM_ SG_ 2451052545 M001_flag_BalanceCell29 "commands module to balance cell 29";
CM_ SG_ 2451052545 M001_flag_BalanceCell30 "commands module to balance cell 30";
CM_ SG_ 2451052545 M001_flag_BalanceCell31 "commands module to balance cell 31";
CM_ SG_ 2451052545 M001_flag_BalanceCell32 "commands module to balance cell 32";
CM_ BO_ 2415945729 "BMS-Slave serial numbers (BMS-Slave serial numbers)";
CM_ BO_ 2415949825 "Data stored in the EEPROM (Data stored in the EEPROM)";
CM_ SG_ 2415949825 M001_val_EEPROMIndex "Index of EEPROM Data";
CM_ SG_ 2415949825 M001_WriteDynamicAreaANext "shows which dynamic area will be written next";
CM_ SG_ 2415949825 M001_val_EEPROMData "EEPROM data";
CM_ BO_ 2416474113 "Write Data to the EEPROM (Write Data to the EEPROM)";
CM_ SG_ 2416474113 M001_val_EEPROMWriteIndex "Index of written EEPROM Data";
CM_ SG_ 2416474113 M001_val_EEPROMWriteData "EEPROM write data";
CM_ BO_ 2416482305 "Change EEPROM dynamic area (Change EEPROM dynamic area)";
CM_ SG_ 2416482305 M001_val_Magic "Magic to ensure safety";
CM_ SG_ 2416482305 M001_WriteDynamicAreaANext "shows which dynamic area will be written next";
CM_ BO_ 2416478209 "Starts action for all modules in daisy-chain (Starts action for all modules in daisy-chain)";
CM_ SG_ 2416478209 M001_val_Magic "Magic to ensure safety";
CM_ BO_ 2415953921 "Informations about internal temperatures of the ICs on the module board (Informations about internal temperatures of the ICs on the module board)";
CM_ SG_ 2415953921 M001_act_T_IC1_Temp_C "internal temperature of IC 1 on module board";
CM_ SG_ 2415953921 M001_act_T_IC2_Temp_C "internal temperature of IC 2 on module board";
CM_ SG_ 2415953921 M001_act_T_IC3_Temp_C "internal temperature of IC 3 on module board";
CM_ SG_ 2415953921 M001_act_T_IC4_Temp_C "internal temperature of IC 4 on module board";
CM_ BO_ 2415958017 "Digital power supply values of the ICs on the module board (Digital power supply values of the ICs on the module board)";
CM_ SG_ 2415958017 M001_act_U_DigiPower_IC1_mV "Digital Power Supply Voltage of IC 1 on the module board";
CM_ SG_ 2415958017 M001_act_U_DigiPower_IC2_mV "Digital Power Supply Voltage of IC 2 on the module board";
CM_ SG_ 2415958017 M001_act_U_DigiPower_IC3_mV "Digital Power Supply Voltage of IC 3 on the module board";
CM_ SG_ 2415958017 M001_act_U_DigiPower_IC4_mV "Digital Power Supply Voltage of IC 4 on the module board";
CM_ BO_ 2415962113 "Analog power supply values of the ICs on the module board (Analog power supply values of the ICs on the module board)";
CM_ SG_ 2415962113 M001_act_U_AnalogPower_IC1_mV "Analog Power Supply Voltage of IC 1 on the module board";
CM_ SG_ 2415962113 M001_act_U_AnalogPower_IC2_mV "Analog Power Supply Voltage of IC 2 on the module board";
CM_ SG_ 2415962113 M001_act_U_AnalogPower_IC3_mV "Analog Power Supply Voltage of IC 3 on the module board";
CM_ SG_ 2415962113 M001_act_U_AnalogPower_IC4_mV "Analog Power Supply Voltage of IC 4 on the module board";
CM_ BO_ 2415966209 "Values of the external reference voltages of the ICs on the module board (Values of the external reference voltages of the ICs on the module board)";
CM_ SG_ 2415966209 M001_act_U_RefVoltage_IC1_mV "Reference Voltage of IC 1 on the module board";
CM_ SG_ 2415966209 M001_act_U_RefVoltage_IC2_mV "Reference Voltage of IC 2 on the module board";
CM_ SG_ 2415966209 M001_act_U_RefVoltage_IC3_mV "Reference Voltage of IC 3 on the module board";
CM_ SG_ 2415966209 M001_act_U_RefVoltage_IC4_mV "Reference Voltage of IC 4 on the module board";
CM_ BO_ 2415970305 "Sum of the cell voltages of ICs on the module board (Sum of the cell voltages of ICs on the module board)";
CM_ SG_ 2415970305 M001_act_U_SumOfCell_IC1_V "Sum of Cells of IC 1 on the module board";
CM_ SG_ 2415970305 M001_act_U_SumOfCell_IC2_V "Sum of Cells of IC 2 on the module board";
CM_ SG_ 2415970305 M001_act_U_SumOfCell_IC3_V "Sum of Cells of IC 3 on the module board";
CM_ SG_ 2415970305 M001_act_U_SumOfCell_IC4_V "Sum of Cells of IC 4 on the module board";
CM_ BO_ 2415974401 "over voltage Flags for all cells (over voltage Flags for all cells)";
CM_ SG_ 2415974401 M001_flag_OvervoltageCell1 "Flag for overvoltage of cell 1";
CM_ SG_ 2415974401 M001_flag_OvervoltageCell2 "Flag for overvoltage of cell 2";
CM_ SG_ 2415974401 M001_flag_OvervoltageCell3 "Flag for overvoltage of cell 3";
CM_ SG_ 2415974401 M001_flag_OvervoltageCell4 "Flag for overvoltage of cell 4";
CM_ SG_ 2415974401 M001_flag_OvervoltageCell5 "Flag for overvoltage of cell 5";
CM_ SG_ 2415974401 M001_flag_OvervoltageCell6 "Flag for overvoltage of cell 6";
CM_ SG_ 2415974401 M001_flag_OvervoltageCell7 "Flag for overvoltage of cell 7";
CM_ SG_ 2415974401 M001_flag_OvervoltageCell8 "Flag for overvoltage of cell 8";
CM_ SG_ 2415974401 M001_flag_OvervoltageCell9 "Flag for overvoltage of cell 9";
CM_ SG_ 2415974401 M001_flag_OvervoltageCell10 "Flag for overvoltage of cell 10";
CM_ SG_ 2415974401 M001_flag_OvervoltageCell11 "Flag for overvoltage of cell 11";
CM_ SG_ 2415974401 M001_flag_OvervoltageCell12 "Flag for overvoltage of cell 12";
CM_ SG_ 2415974401 M001_flag_OvervoltageCell13 "Flag for overvoltage of cell 13";
CM_ SG_ 2415974401 M001_flag_OvervoltageCell14 "Flag for overvoltage of cell 14";
CM_ SG_ 2415974401 M001_flag_OvervoltageCell15 "Flag for overvoltage of cell 15";
CM_ SG_ 2415974401 M001_flag_OvervoltageCell16 "Flag for overvoltage of cell 16";
CM_ SG_ 2415974401 M001_flag_OvervoltageCell17 "Flag for overvoltage of cell 17";
CM_ SG_ 2415974401 M001_flag_OvervoltageCell18 "Flag for overvoltage of cell 18";
CM_ SG_ 2415974401 M001_flag_OvervoltageCell19 "Flag for overvoltage of cell 19";
CM_ SG_ 2415974401 M001_flag_OvervoltageCell20 "Flag for overvoltage of cell 20";
CM_ SG_ 2415974401 M001_flag_OvervoltageCell21 "Flag for overvoltage of cell 21";
CM_ SG_ 2415974401 M001_flag_OvervoltageCell22 "Flag for overvoltage of cell 22";
CM_ SG_ 2415974401 M001_flag_OvervoltageCell23 "Flag for overvoltage of cell 23";
CM_ SG_ 2415974401 M001_flag_OvervoltageCell24 "Flag for overvoltage of cell 24";
CM_ SG_ 2415974401 M001_flag_OvervoltageCell25 "Flag for overvoltage of cell 25";
CM_ SG_ 2415974401 M001_flag_OvervoltageCell26 "Flag for overvoltage of cell 26";
CM_ SG_ 2415974401 M001_flag_OvervoltageCell27 "Flag for overvoltage of cell 27";
CM_ SG_ 2415974401 M001_flag_OvervoltageCell28 "Flag for overvoltage of cell 28";
CM_ SG_ 2415974401 M001_flag_OvervoltageCell29 "Flag for overvoltage of cell 29";
CM_ SG_ 2415974401 M001_flag_OvervoltageCell30 "Flag for overvoltage of cell 30";
CM_ SG_ 2415974401 M001_flag_OvervoltageCell31 "Flag for overvoltage of cell 31";
CM_ SG_ 2415974401 M001_flag_OvervoltageCell32 "Flag for overvoltage of cell 32";
CM_ SG_ 2415974401 M001_flag_OvervoltageCell33 "Flag for overvoltage of cell 33";
CM_ SG_ 2415974401 M001_flag_OvervoltageCell34 "Flag for overvoltage of cell 34";
CM_ SG_ 2415974401 M001_flag_OvervoltageCell35 "Flag for overvoltage of cell 35";
CM_ SG_ 2415974401 M001_flag_OvervoltageCell36 "Flag for overvoltage of cell 36";
CM_ SG_ 2415974401 M001_flag_OvervoltageCell37 "Flag for overvoltage of cell 37";
CM_ SG_ 2415974401 M001_flag_OvervoltageCell38 "Flag for overvoltage of cell 38";
CM_ SG_ 2415974401 M001_flag_OvervoltageCell39 "Flag for overvoltage of cell 39";
CM_ SG_ 2415974401 M001_flag_OvervoltageCell40 "Flag for overvoltage of cell 40";
CM_ BO_ 2415978497 "under voltage Flags for all cells (under voltage Flags for all cells)";
CM_ SG_ 2415978497 M001_flag_UndervoltageCell1 "Flag for undervoltage of cell 1";
CM_ SG_ 2415978497 M001_flag_UndervoltageCell2 "Flag for undervoltage of cell 2";
CM_ SG_ 2415978497 M001_flag_UndervoltageCell3 "Flag for undervoltage of cell 3";
CM_ SG_ 2415978497 M001_flag_UndervoltageCell4 "Flag for undervoltage of cell 4";
CM_ SG_ 2415978497 M001_flag_UndervoltageCell5 "Flag for undervoltage of cell 5";
CM_ SG_ 2415978497 M001_flag_UndervoltageCell6 "Flag for undervoltage of cell 6";
CM_ SG_ 2415978497 M001_flag_UndervoltageCell7 "Flag for undervoltage of cell 7";
CM_ SG_ 2415978497 M001_flag_UndervoltageCell8 "Flag for undervoltage of cell 8";
CM_ SG_ 2415978497 M001_flag_UndervoltageCell9 "Flag for undervoltage of cell 9";
CM_ SG_ 2415978497 M001_flag_UndervoltageCell10 "Flag for undervoltage of cell 10";
CM_ SG_ 2415978497 M001_flag_UndervoltageCell11 "Flag for undervoltage of cell 11";
CM_ SG_ 2415978497 M001_flag_UndervoltageCell12 "Flag for undervoltage of cell 12";
CM_ SG_ 2415978497 M001_flag_UndervoltageCell13 "Flag for undervoltage of cell 13";
CM_ SG_ 2415978497 M001_flag_UndervoltageCell14 "Flag for undervoltage of cell 14";
CM_ SG_ 2415978497 M001_flag_UndervoltageCell15 "Flag for undervoltage of cell 15";
CM_ SG_ 2415978497 M001_flag_UndervoltageCell16 "Flag for undervoltage of cell 16";
CM_ SG_ 2415978497 M001_flag_UndervoltageCell17 "Flag for undervoltage of cell 17";
CM_ SG_ 2415978497 M001_flag_UndervoltageCell18 "Flag for undervoltage of cell 18";
CM_ SG_ 2415978497 M001_flag_UndervoltageCell19 "Flag for undervoltage of cell 19";
CM_ SG_ 2415978497 M001_flag_UndervoltageCell20 "Flag for undervoltage of cell 20";
CM_ SG_ 2415978497 M001_flag_UndervoltageCell21 "Flag for undervoltage of cell 21";
CM_ SG_ 2415978497 M001_flag_UndervoltageCell22 "Flag for undervoltage of cell 22";
CM_ SG_ 2415978497 M001_flag_UndervoltageCell23 "Flag for undervoltage of cell 23";
CM_ SG_ 2415978497 M001_flag_UndervoltageCell24 "Flag for undervoltage of cell 24";
CM_ SG_ 2415978497 M001_flag_UndervoltageCell25 "Flag for undervoltage of cell 25";
CM_ SG_ 2415978497 M001_flag_UndervoltageCell26 "Flag for undervoltage of cell 26";
CM_ SG_ 2415978497 M001_flag_UndervoltageCell27 "Flag for undervoltage of cell 27";
CM_ SG_ 2415978497 M001_flag_UndervoltageCell28 "Flag for undervoltage of cell 28";
CM_ SG_ 2415978497 M001_flag_UndervoltageCell29 "Flag for undervoltage of cell 29";
CM_ SG_ 2415978497 M001_flag_UndervoltageCell30 "Flag for undervoltage of cell 30";
CM_ SG_ 2415978497 M001_flag_UndervoltageCell31 "Flag for undervoltage of cell 31";
CM_ SG_ 2415978497 M001_flag_UndervoltageCell32 "Flag for undervoltage of cell 32";
CM_ SG_ 2415978497 M001_flag_UndervoltageCell33 "Flag for undervoltage of cell 33";
CM_ SG_ 2415978497 M001_flag_UndervoltageCell34 "Flag for undervoltage of cell 34";
CM_ SG_ 2415978497 M001_flag_UndervoltageCell35 "Flag for undervoltage of cell 35";
CM_ SG_ 2415978497 M001_flag_UndervoltageCell36 "Flag for undervoltage of cell 36";
CM_ SG_ 2415978497 M001_flag_UndervoltageCell37 "Flag for undervoltage of cell 37";
CM_ SG_ 2415978497 M001_flag_UndervoltageCell38 "Flag for undervoltage of cell 38";
CM_ SG_ 2415978497 M001_flag_UndervoltageCell39 "Flag for undervoltage of cell 39";
CM_ SG_ 2415978497 M001_flag_UndervoltageCell40 "Flag for undervoltage of cell 40";
CM_ BO_ 2415982593 "Write Data to the EEPROM (Write Data to the EEPROM)";
CM_ SG_ 2415982593 M001_conf_IdxOfTempSensor "Index of temperature sensor";
CM_ SG_ 2415982593 M001_conf_RefTemperature_C "calibration reference temperature";
CM_ SG_ 2415982593 M001_conf_A_CurrentOffsetA_mA "calibration current offset A";
CM_ SG_ 2415982593 M001_conf_A_CurrentOffsetB_mA "calibration current offset B";
CM_ SG_ 2415982593 M001_conf_A_CurrentFactorA_mA "calibration current factor A";
CM_ SG_ 2415982593 M001_conf_A_CurrentFactorB_mA "calibration current factor B";
CM_ SG_ 2415982593 M001_conf_U_VoltageIC1_mV "calibration voltage IC1";
CM_ SG_ 2415982593 M001_conf_U_VoltageIC2_mV "calibration voltage IC2";
CM_ SG_ 2415982593 M001_conf_U_VoltageIC3_mV "calibration voltage IC3";
CM_ SG_ 2415982593 M001_conf_U_VoltageIC4_mV "calibration voltage IC4";
CM_ SG_ 2415982593 M001_conf_NewSerialNrLo "new serial number lower part";
CM_ SG_ 2415982593 M001_conf_NewSerialNrHi "new serial number higher part";
CM_ SG_ 2415982593 M001_conf_PCBNewSerialNrLo "PCB new serial number lower part";
CM_ SG_ 2415982593 M001_conf_PCBNewSerialNrHi "PCB new serial number higher part";
CM_ SG_ 2415982593 M001_conf_NewModuleTypeMajor "new module type (Type)";
CM_ SG_ 2415982593 M001_conf_NewModuleTypeMinor "new module type (Index/revision)";
CM_ SG_ 2415982593 M001_conf_NewPCBTypeMajor "new PCB type (Type)";
CM_ SG_ 2415982593 M001_conf_NewPCBTypeMinor "new PCB type (Index/revision)";
CM_ SG_ 2415982593 M001_conf_NewICTypeMajor "new IC type (Type)";
CM_ SG_ 2415982593 M001_conf_NewICTypeMinor "new IC type (Index/revision)";
CM_ SG_ 2415982593 M001_conf_NewCellTypeMajor "new Cell type (Type)";
CM_ SG_ 2415982593 M001_conf_NewCellTypeMinor "new Cell type (Index/revision)";
CM_ SG_ 2415982593 M001_conf_TopologyMajor "Number of cells in serial";
CM_ SG_ 2415982593 M001_conf_TopologyMinor "Number of parallel cells";
CM_ BO_ 2281706497 "SCU status message (SCU status message)";
CM_ SG_ 2281706497 SCU1_stat_Init "initialisation of SCU components";
CM_ SG_ 2281706497 SCU1_stat_Run "selftests are finished";
CM_ SG_ 2281706497 SCU1_stat_Error "SCU has encountered an error";
CM_ SG_ 2281706497 SCU1_stat_Config "SCU is beeing configured";
CM_ SG_ 2281706497 SCU1_stat_LimpHome "limp home modus with limited functionallity";
CM_ SG_ 2281706497 SCU1_stat_Diag "SCU is in diagnostic mode";
CM_ SG_ 2281706497 SCU1_stat_Shutdown "KL15 is off, SCU shutdown started";
CM_ SG_ 2281706497 SCU1_stat_ART_Started "Afterrun test started";
CM_ SG_ 2281706497 SCU1_stat_ART_IsActive "Afterrun test is running";
CM_ SG_ 2281706497 SCU1_stat_ART_NoError "No Error While After Run Test";
CM_ SG_ 2281706497 SCU1_stat_ART_BMSS_Restart "Restart of BMS-Slaves is performed";
CM_ SG_ 2281706497 SCU1_flag_PowerContPos "state of power contactor +";
CM_ SG_ 2281706497 SCU1_flag_PowerContNeg "state of power contactor -";
CM_ SG_ 2281706497 SCU1_flag_PowerContPre "state of power contactor precharge";
CM_ SG_ 2281706497 SCU1_flag_PowerContExtAux "state of extended aux power contactor";
CM_ SG_ 2281706497 SCU1_stat_ConOnProtect "contactor protection flag after contactor drop-out";
CM_ SG_ 2281706497 SCU1_flag_ShuntResCalibration "state of the shunt resistance calibration";
CM_ SG_ 2281706497 SCU1_flag_EoL_Mode "state of the EoL mode";
CM_ SG_ 2281706497 SCU1_flag_VSenserelayPosInt "state of sense relay Tray+ intern";
CM_ SG_ 2281706497 SCU1_flag_VSenserelayNegInt "state of sense relay Tray- intern";
CM_ SG_ 2281706497 SCU1_flag_VSenserelayPosExt "state of sense relay Tray+ extern";
CM_ SG_ 2281706497 SCU1_flag_VSenserelayNegExt "state of sense relay Tray- extern";
CM_ SG_ 2281706497 SCU1_flag_eStopLoopNotClosed "status of eStop loop";
CM_ SG_ 2281706497 SCU1_flag_InterventioneStop "status of intervention of SCU on eStop loop";
CM_ SG_ 2281706497 SCU1_flag_InterLockError "status of interlock (current is out of range)";
CM_ SG_ 2281706497 SCU1_flag_SourceInterlockLoop "status of SCU source of interlock loop";
CM_ SG_ 2281706497 SCU1_flag_KL15 "status of KL 15";
CM_ SG_ 2281706497 SCU1_flag_BMMSafe "status of BMM safe";
CM_ SG_ 2281706497 SCU1_flag_SupplyMonitorWarning "status of supply monitor warning";
CM_ SG_ 2281706497 SCU1_flag_CANGatewayStatus "status of CAN gateway";
CM_ SG_ 2281706497 SCU1_flag_Led1 "status od LED 1";
CM_ SG_ 2281706497 SCU1_flag_Led2 "status of LED 2";
CM_ SG_ 2281706497 SCU1_flag_Led3 "status of LED 3";
CM_ SG_ 2281706497 SCU1_flag_Warning "warning flag";
CM_ SG_ 2281706497 SCU1_flag_Alarm "alarm flag";
CM_ SG_ 2281706497 SCU1_flag_SilentCan1 "management message CAN_1 has been silenced";
CM_ SG_ 2281706497 SCU1_flag_SilentCan2 "management message CAN_2 has been silenced";
CM_ SG_ 2281706497 SCU1_flag_HSS1Locked "switch on protection after thermal shut off of power MOS-FET";
CM_ SG_ 2281706497 SCU1_flag_HSS2Locked "switch on protection after thermal shut off of power MOS-FET";
CM_ SG_ 2281706497 SCU1_flag_HSS3Locked "switch on protection after thermal shut off of power MOS-FET";
CM_ SG_ 2281706497 SCU1_flag_HSS4Locked "switch on protection after thermal shut off of power MOS-FET";
CM_ SG_ 2281706497 SCU1_flag_CompChipWarning "state of companion chip warning";
CM_ SG_ 2281706497 SCU1_flag_PowerProtWarning "state of power protection warning";
CM_ SG_ 2281706497 SCU1_flag_SafetyEnable1 "state of safety enable 1";
CM_ SG_ 2281706497 SCU1_flag_SafetyEnable2 "state of safety enable 2";
CM_ SG_ 2281706497 SCU1_flag_eStopBrakeOut "state of eStop brake out";
CM_ SG_ 2281706497 SCU1_flag_ForceSave "state of force save state";
CM_ SG_ 2281706497 SCU1_flag_CAN1BusOff "bus off state of CAN bus 1";
CM_ SG_ 2281706497 SCU1_flag_CAN2BusOff "bus off state of CAN bus 2";
CM_ SG_ 2281706497 SCU1_flag_ContStuckChk "state of contactor stuck at check";
CM_ SG_ 2281706497 SCU1_flag_ExtAuxStuckChk "state of extended aux contactor stuck at check";
CM_ SG_ 2281706497 SCU1_flag_PrechargeOK "Completed precharge successfully";
CM_ BO_ 2449482753 "percentual status of highside-switch-outputs (percentual status of highside-switch-outputs)";
CM_ SG_ 2449482753 SCU1_act_HighsideSwitch1_pct "% value of highside switch 1";
CM_ SG_ 2449482753 SCU1_act_HighsideSwitch2_pct "% value of highside switch 2";
CM_ SG_ 2449482753 SCU1_act_HighsideSwitch3_pct "% value of highside switch 3";
CM_ SG_ 2449482753 SCU1_act_HighsideSwitch4_pct "% value of highside switch 4";
CM_ BO_ 2449486849 "highside switch currents (highside switch currents)";
CM_ SG_ 2449486849 SCU1_act_I_HSSwitch1Curr_mA "current of highside switch 1";
CM_ SG_ 2449486849 SCU1_act_I_HSSwitch2Curr_mA "current of highside switch 2";
CM_ SG_ 2449486849 SCU1_act_I_HSSwitch3Curr_mA "current of highside switch 3";
CM_ SG_ 2449486849 SCU1_act_I_HSSwitch4Curr_mA "current of highside switch 4";
CM_ BO_ 2449490945 "Coil currents of contactors (Coil currents of contactors)";
CM_ SG_ 2449490945 SCU1_act_I_CoilCurrContPos_mA "coil current of + contactor";
CM_ SG_ 2449490945 SCU1_act_I_CoilCurrContNeg_mA "coil current of - contactor";
CM_ SG_ 2449490945 SCU1_act_I_CoilCurrContPre_mA "coil current of precharge contactor";
CM_ SG_ 2449490945 SCU1_act_I_CoilCurrContAux_mA "coil current of aux contactor";
CM_ BO_ 2315277313 "SCU currents (SCU currents)";
CM_ SG_ 2315277313 SCU1_act_I_CurrentSensHigh_A "current sensor (high)";
CM_ SG_ 2315277313 SCU1_act_I_CurrentSensLow_A "current sensor (low)";
CM_ SG_ 2315277313 SCU1_act_I_CurrentSens2High_A "second current sensor (high)";
CM_ SG_ 2315277313 SCU1_act_I_CurrentSens2Low_A "second current sensor (low)";
CM_ BO_ 2449499137 "SCU Temperatures (SCU Temperatures)";
CM_ SG_ 2449499137 SCU1_act_V_SenseExt1_mV "External Voltage Sensor 1";
CM_ SG_ 2449499137 SCU1_act_V_SenseExt2_mV "External Voltage Sensor 2";
CM_ SG_ 2449499137 SCU1_act_T_BoardTemperature_C "Board Temperature (measured by ADC)";
CM_ BO_ 2449503233 "SCU operating voltages (SCU operating voltages)";
CM_ SG_ 2449503233 SCU1_act_U_Contact30_V "KL30";
CM_ SG_ 2449503233 SCU1_act_U_BMMSafe_V "BMM safe power";
CM_ SG_ 2449503233 SCU1_act_U_HSSupply12_V "Highside- Switch-Powersupply voltage 1-2";
CM_ SG_ 2449503233 SCU1_act_U_HSSupply34_V "Highside- Switch-Powersupply voltage 3-4";
CM_ BO_ 2315314177 "SCU battery voltages + (SCU battery voltages +)";
CM_ SG_ 2315314177 SCU1_act_U_BatPos_V "Bat+";
CM_ SG_ 2315314177 SCU1_act_U_SysPos_V "Sys+";
CM_ BO_ 2315318273 "SCU battery voltages - (SCU battery voltages -)";
CM_ SG_ 2315318273 SCU1_act_U_BatNeg_V "Bat-";
CM_ SG_ 2315318273 SCU1_act_U_SysNeg_V "Sys-";
CM_ BO_ 2583725057 "SCU battery voltages diagnostic (SCU battery voltages diagnostic)";
CM_ SG_ 2583725057 SCU1_act_U_TrayPosExt_V "Tray+ to ground extern";
CM_ SG_ 2583725057 SCU1_act_U_TrayNegExt_V "Tray- extern";
CM_ SG_ 2583725057 SCU1_act_U_TrayPosInt_V "Tray+ intern";
CM_ SG_ 2583725057 SCU1_act_U_TrayNegInt_V "Tray- intern";
CM_ BO_ 2449511425 "SCU tray voltages (SCU tray voltages)";
CM_ SG_ 2449511425 SCU1_act_U_TrayVoltageLocal_V "Tray local HV voltage";
CM_ SG_ 2449511425 SCU1_act_U_ChassisGndVoltage_V "chassis to ground voltage";
CM_ SG_ 2449511425 SCU1_act_U_ReferenceVoltage_V "independent SCU reference voltage";
CM_ BO_ 2449515521 "Isolation- and contactor stuck voltages (frozen at init) (Isolation- and contactor stuck voltages (frozen at init))";
CM_ SG_ 2449515521 SCU1_diag_U_TrayPosExt_U_frz "Tray+ extern";
CM_ SG_ 2449515521 SCU1_diag_U_TrayNegExt_U_frz "Tray- extern";
CM_ SG_ 2449515521 SCU1_diag_U_TrayPosInt_U_frz "Tray+ intern";
CM_ SG_ 2449515521 SCU1_diag_U_TrayNegInt_U_frz "Tray- intern";
CM_ BO_ 2449519617 "SCU error message (SCU error message)";
CM_ SG_ 2449519617 SCU1_err_Number "error number";
CM_ SG_ 2449519617 SCU1_err_Level "error level";
CM_ SG_ 2449519617 SCU1_err_Value "error value";
CM_ SG_ 2449519617 SCU1_err_Source "error source";
CM_ BO_ 2449523713 "SCU warning message (SCU warning message)";
CM_ SG_ 2449523713 SCU1_wf_InvalidData "short circuit or open temperature sensor";
CM_ SG_ 2449523713 SCU1_wf_ContactorWrongState "tbd";
CM_ SG_ 2449523713 SCU1_wf_CurrSens "i sensor error occurred";
CM_ SG_ 2449523713 SCU1_wf_ContDam "contactors damaged";
CM_ SG_ 2449523713 SCU1_wf_RefVoltErrorMax "refernce voltage to high";
CM_ SG_ 2449523713 SCU1_wf_RefVoltErrorMin "refernce voltage to low";
CM_ SG_ 2449523713 SCU1_wf_KL30SafeMax "KL30-Safe max";
CM_ SG_ 2449523713 SCU1_wf_KL30SafeMin "KL30-Safe min";
CM_ SG_ 2449523713 SCU1_wf_KL30SafeOff "BMS-M-SafePwr was switched off (HW detection)";
CM_ SG_ 2449523713 SCU1_wf_ContactorDropOut "a contactor drop out occured";
CM_ SG_ 2449523713 SCU1_wf_BoardTemp "ECU/IC board temperature too high/low";

BA_DEF_  "BusType" STRING ;
BA_DEF_ BO_  "GenMsgCycleTime" INT 0 65535;
BA_DEF_ SG_  "GenSigStartValue" FLOAT -3.4E+038 3.4E+038;

BA_DEF_DEF_  "BusType" "CAN";
BA_DEF_DEF_  "GenMsgCycleTime" 0;
BA_DEF_DEF_  "GenSigStartValue" 0;

BA_ "GenMsgCycleTime" BO_ 2415922177 1000;
BA_ "GenMsgCycleTime" BO_ 2415922178 1000;
BA_ "GenMsgCycleTime" BO_ 2415922179 1000;
BA_ "GenMsgCycleTime" BO_ 2415922180 1000;
BA_ "GenMsgCycleTime" BO_ 2415922181 1000;
BA_ "GenMsgCycleTime" BO_ 2415922182 1000;
BA_ "GenMsgCycleTime" BO_ 2415922183 1000;
BA_ "GenMsgCycleTime" BO_ 2415922184 1000;
BA_ "GenMsgCycleTime" BO_ 2415922185 1000;
BA_ "GenMsgCycleTime" BO_ 2415922186 1000;
BA_ "GenMsgCycleTime" BO_ 2415922187 1000;
BA_ "GenMsgCycleTime" BO_ 2415922188 1000;
BA_ "GenMsgCycleTime" BO_ 2415922189 1000;
BA_ "GenMsgCycleTime" BO_ 2415922190 1000;
BA_ "GenMsgCycleTime" BO_ 2415922191 1000;
BA_ "GenMsgCycleTime" BO_ 2415922192 1000;
BA_ "GenMsgCycleTime" BO_ 2415922193 1000;
BA_ "GenMsgCycleTime" BO_ 2415922194 1000;
BA_ "GenMsgCycleTime" BO_ 2415922195 1000;
BA_ "GenMsgCycleTime" BO_ 2415922196 1000;
BA_ "GenMsgCycleTime" BO_ 2415925249 1000;
BA_ "GenMsgCycleTime" BO_ 2415929345 1000;
BA_ "GenMsgCycleTime" BO_ 2415937537 1000;
BA_ "GenMsgCycleTime" BO_ 2415941633 1000;
BA_ "GenMsgCycleTime" BO_ 2415986689 1000;
BA_ "GenMsgCycleTime" BO_ 2415933441 1000;
BA_ "GenMsgCycleTime" BO_ 2415945729 1000;
BA_ "GenMsgCycleTime" BO_ 2415949825 1000;
BA_ "GenMsgCycleTime" BO_ 2416474113 1000;
BA_ "GenMsgCycleTime" BO_ 2415953921 1000;
BA_ "GenMsgCycleTime" BO_ 2415958017 1000;
BA_ "GenMsgCycleTime" BO_ 2415962113 1000;
BA_ "GenMsgCycleTime" BO_ 2415966209 1000;
BA_ "GenMsgCycleTime" BO_ 2415970305 1000;
BA_ "GenMsgCycleTime" BO_ 2415974401 1000;
BA_ "GenMsgCycleTime" BO_ 2415978497 1000;
BA_ "GenMsgCycleTime" BO_ 2415982593 1000;
BA_ "GenMsgCycleTime" BO_ 2281706497 40;
BA_ "GenMsgCycleTime" BO_ 2449482753 100;
BA_ "GenMsgCycleTime" BO_ 2449486849 100;
BA_ "GenMsgCycleTime" BO_ 2449490945 100;
BA_ "GenMsgCycleTime" BO_ 2315277313 100;
BA_ "GenMsgCycleTime" BO_ 2449499137 1000;
BA_ "GenMsgCycleTime" BO_ 2449503233 100;
BA_ "GenMsgCycleTime" BO_ 2315314177 100;
BA_ "GenMsgCycleTime" BO_ 2315318273 100;
BA_ "GenMsgCycleTime" BO_ 2583725057 100;
BA_ "GenMsgCycleTime" BO_ 2449511425 100;
BA_ "GenMsgCycleTime" BO_ 2449515521 100;
BA_ "GenMsgCycleTime" BO_ 2449519617 100;
BA_ "GenMsgCycleTime" BO_ 2449523713 100;

BA_ "GenSigStartValue" SG_ 2416478208 M001_FixValues_LockIDPageCommand 9780392;

VAL_ 2550712321 M001_CalibrationMessage_Mux 5920170 "Temp" 1509971370 "CurrentOffsetA" 1515869610 "CurrentOffsetB" 1522226602 "CurrentFactorA" -1157605974 "CurrentFactorB" -1151707734 "VoltIC1" 1527469482 "VoltIC2" -1174383190 "VoltIC3" 1522161066 "VoltIC4";
VAL_ 2550716417 M001_ConfigurationMessage_Mux -791631275 "SerialnumberLow" -623203755 "SerialnumberHigh" -623859115 "PCBSerialnumberLow" 218999381 "PCBSerialnumberHigh" -1381127595 "ModuleType" 298756693 "PCBType" -828265899 "ICType" -837703083 "CellType" -1520784811 "Topology";
VAL_ 2415945729 M001_SlaveSerials_Mux 0 "Production" 1 "Electronics";
VAL_ 2416474113 M001_WriteEEPROMData_Mux 14318101 "WriteData";
VAL_ 2415982593 M001_SendEEPROMDataEOL_Mux 5920170 "Temp" 1509971370 "CurrentOffsetA" 1515869610 "CurrentOffsetB" 1522226602 "CurrentFactorA" -1157605974 "CurrentFactorB" -1151707734 "VoltIC1" 1527469482 "VoltIC2" -1174383190 "VoltIC3" 1522161066 "VoltIC4" -791631275 "SerialnumberLow" -623203755 "SerialnumberHigh" -623859115 "PCBSerialnumberLow" 218999381 "PCBSerialnumberHigh" -1381127595 "ModuleType" 298756693 "PCBType" -828265899 "ICType" -837703083 "CellType" -1520784811 "Topology";
VAL_ 2415941633 M001_flag_CalibrationDone 0 "no" 1 "yes";
VAL_ 2415941633 M001_flag_CalibrationIncomp 0 "no" 1 "yes";
VAL_ 2415941633 M001_flag_CalibrationError 0 "no" 1 "yes";
VAL_ 2415941633 M001_flag_EEPROMError 0 "no" 1 "yes";
VAL_ 2415941633 M001_flag_WDGError 0 "no" 1 "yes";
VAL_ 2415941633 M001_flag_ConfigDone 0 "no" 1 "yes";
VAL_ 2415941633 M001_flag_TempCalErr 0 "no" 1 "yes";
VAL_ 2415941633 M001_flag_SerialMiss 0 "no" 1 "yes";
VAL_ 2415941633 M001_flag_ThermalShtDwn_IC1 0 "no" 1 "yes";
VAL_ 2415941633 M001_flag_ThermalShtDwn_IC2 0 "no" 1 "yes";
VAL_ 2415941633 M001_flag_ThermalShtDwn_IC3 0 "no" 1 "yes";
VAL_ 2415941633 M001_flag_ThermalShtDwn_IC4 0 "no" 1 "yes";
VAL_ 2415941633 M001_flag_SelfTestPassed 0 "no" 1 "yes";
VAL_ 2415941633 M001_flag_SM_PollTimeout 0 "no" 1 "yes";
VAL_ 2415941633 M001_flag_NoSafRel_PollTimeout 0 "no" 1 "yes";
VAL_ 2415941633 M001_flag_SM_BadCRC_IC1 0 "no" 1 "yes";
VAL_ 2415941633 M001_flag_SM_BadCRC_IC2 0 "no" 1 "yes";
VAL_ 2415941633 M001_flag_SM_BadCRC_IC3 0 "no" 1 "yes";
VAL_ 2415941633 M001_flag_SM_BadCRC_IC4 0 "no" 1 "yes";
VAL_ 2415941633 M001_flag_NoSafRel_BadCRC_IC1 0 "no" 1 "yes";
VAL_ 2415941633 M001_flag_NoSafRel_BadCRC_IC2 0 "no" 1 "yes";
VAL_ 2415941633 M001_flag_NoSafRel_BadCRC_IC3 0 "no" 1 "yes";
VAL_ 2415941633 M001_flag_NoSafRel_BadCRC_IC4 0 "no" 1 "yes";
VAL_ 2415941633 M001_flag_BadCRC_IC1 0 "no" 1 "yes";
VAL_ 2415941633 M001_flag_BadCRC_IC2 0 "no" 1 "yes";
VAL_ 2415941633 M001_flag_BadCRC_IC3 0 "no" 1 "yes";
VAL_ 2415941633 M001_flag_BadCRC_IC4 0 "no" 1 "yes";
VAL_ 2415941633 M001_flag_PollTimeout 0 "no" 1 "yes";
VAL_ 2415941633 M001_flag_ComplSafAreaCRCErr 0 "no" 1 "yes";
VAL_ 2415941633 M001_flag_ComplStatAreaCRCErr 0 "no" 1 "yes";
VAL_ 2415941633 M001_flag_ComplDynAreaCRCErr 0 "no" 1 "yes";
VAL_ 2415941633 M001_flag_InitialisationFail 0 "no" 1 "yes";
VAL_ 2415941633 M001_flag_SingleSafAreaCRCErr 0 "no" 1 "yes";
VAL_ 2415941633 M001_flag_SingleStatAreaCRCErr 0 "no" 1 "yes";
VAL_ 2415941633 M001_flag_SingleDynAreaCRCErr 0 "no" 1 "yes";
VAL_ 2415941633 M001_flag_SafAreaMismatch 0 "no" 1 "yes";
VAL_ 2415941633 M001_flag_StatAreaMismatch 0 "no" 1 "yes";
VAL_ 2415941633 M001_flag_IDPageNotLocked 0 "no" 1 "yes";
VAL_ 2415941633 M001_flag_I2CCommunicationFail 0 "no" 1 "yes";
VAL_ 2415941633 M001_flag_EEPROMReadFail 0 "no" 1 "yes";
VAL_ 2415941633 M001_flag_IDPageStatusReadFail 0 "no" 1 "yes";
VAL_ 2415941633 M001_flag_SafAreaWriteFail 0 "no" 1 "yes";
VAL_ 2415941633 M001_flag_StatreaWriteFail 0 "no" 1 "yes";
VAL_ 2415941633 M001_flag_DynAreaWriteFail 0 "no" 1 "yes";
VAL_ 2415941633 M001_flag_SafAreaReadFail 0 "no" 1 "yes";
VAL_ 2415941633 M001_flag_StatAreaReadFail 0 "no" 1 "yes";
VAL_ 2415941633 M001_flag_DynAreaReadFail 0 "no" 1 "yes";
VAL_ 2415941633 M001_flag_VerifySafWriteFail 0 "no" 1 "yes";
VAL_ 2415941633 M001_flag_VerifyStatWriteFail 0 "no" 1 "yes";
VAL_ 2415941633 M001_flag_VerifyDynWriteFail 0 "no" 1 "yes";
VAL_ 2415986689 M001_OpenWireDetectedCV_IC1 0 "no" 1 "yes";
VAL_ 2415986689 M001_ADCOverlapTestFailed_IC1 0 "no" 1 "yes";
VAL_ 2415986689 M001_ADCSefttestCVFailed_IC1 0 "no" 1 "yes";
VAL_ 2415986689 M001_ADCSefttestAUXFailed_IC1 0 "no" 1 "yes";
VAL_ 2415986689 M001_OpenWireDetectedAUX_IC1 0 "no" 1 "yes";
VAL_ 2415986689 M001_MUXFail_IC1 0 "no" 1 "yes";
VAL_ 2415986689 M001_BadCRCAccepted_IC1 0 "no" 1 "yes";
VAL_ 2415986689 M001_GPIOAdjShortDetected_IC1 0 "no" 1 "yes";
VAL_ 2415986689 M001_CLRCmdBroken_IC1 0 "no" 1 "yes";
VAL_ 2415986689 M001_WrongPathSelection_IC1 0 "no" 1 "yes";
VAL_ 2415986689 M001_OWCircuitStuckCV_IC1 0 "no" 1 "yes";
VAL_ 2415986689 M001_DischargeCircuitFault_IC1 0 "no" 1 "yes";
VAL_ 2415986689 M001_SM_digRedFail_IC1 0 "no" 1 "yes";
VAL_ 2415986689 M001_SM_ClrRegsFail_IC1 0 "no" 1 "yes";
VAL_ 2415986689 M001_OpenWireDetectedCV_IC2 0 "no" 1 "yes";
VAL_ 2415986689 M001_ADCOverlapTestFailed_IC2 0 "no" 1 "yes";
VAL_ 2415986689 M001_ADCSefttestCVFailed_IC2 0 "no" 1 "yes";
VAL_ 2415986689 M001_ADCSefttestAUXFailed_IC2 0 "no" 1 "yes";
VAL_ 2415986689 M001_OpenWireDetectedAUX_IC2 0 "no" 1 "yes";
VAL_ 2415986689 M001_MUXFail_IC2 0 "no" 1 "yes";
VAL_ 2415986689 M001_BadCRCAccepted_IC2 0 "no" 1 "yes";
VAL_ 2415986689 M001_GPIOAdjShortDetected_IC2 0 "no" 1 "yes";
VAL_ 2415986689 M001_CLRCmdBroken_IC2 0 "no" 1 "yes";
VAL_ 2415986689 M001_WrongPathSelection_IC2 0 "no" 1 "yes";
VAL_ 2415986689 M001_OWCircuitStuckCV_IC2 0 "no" 1 "yes";
VAL_ 2415986689 M001_DischargeCircuitFault_IC2 0 "no" 1 "yes";
VAL_ 2415986689 M001_SM_digRedFail_IC2 0 "no" 1 "yes";
VAL_ 2415986689 M001_SM_ClrRegsFail_IC2 0 "no" 1 "yes";
VAL_ 2415986689 M001_OpenWireDetectedCV_IC3 0 "no" 1 "yes";
VAL_ 2415986689 M001_ADCOverlapTestFailed_IC3 0 "no" 1 "yes";
VAL_ 2415986689 M001_ADCSefttestCVFailed_IC3 0 "no" 1 "yes";
VAL_ 2415986689 M001_ADCSefttestAUXFailed_IC3 0 "no" 1 "yes";
VAL_ 2415986689 M001_OpenWireDetectedAUX_IC3 0 "no" 1 "yes";
VAL_ 2415986689 M001_MUXFail_IC3 0 "no" 1 "yes";
VAL_ 2415986689 M001_BadCRCAccepted_IC3 0 "no" 1 "yes";
VAL_ 2415986689 M001_GPIOAdjShortDetected_IC3 0 "no" 1 "yes";
VAL_ 2415986689 M001_CLRCmdBroken_IC3 0 "no" 1 "yes";
VAL_ 2415986689 M001_WrongPathSelection_IC3 0 "no" 1 "yes";
VAL_ 2415986689 M001_OWCircuitStuckCV_IC3 0 "no" 1 "yes";
VAL_ 2415986689 M001_DischargeCircuitFault_IC3 0 "no" 1 "yes";
VAL_ 2415986689 M001_SM_digRedFail_IC3 0 "no" 1 "yes";
VAL_ 2415986689 M001_SM_ClrRegsFail_IC3 0 "no" 1 "yes";
VAL_ 2415986689 M001_OpenWireDetectedCV_IC4 0 "no" 1 "yes";
VAL_ 2415986689 M001_ADCOverlapTestFailed_IC4 0 "no" 1 "yes";
VAL_ 2415986689 M001_ADCSefttestCVFailed_IC4 0 "no" 1 "yes";
VAL_ 2415986689 M001_ADCSefttestAUXFailed_IC4 0 "no" 1 "yes";
VAL_ 2415986689 M001_OpenWireDetectedAUX_IC4 0 "no" 1 "yes";
VAL_ 2415986689 M001_MUXFail_IC4 0 "no" 1 "yes";
VAL_ 2415986689 M001_BadCRCAccepted_IC4 0 "no" 1 "yes";
VAL_ 2415986689 M001_GPIOAdjShortDetected_IC4 0 "no" 1 "yes";
VAL_ 2415986689 M001_CLRCmdBroken_IC4 0 "no" 1 "yes";
VAL_ 2415986689 M001_WrongPathSelection_IC4 0 "no" 1 "yes";
VAL_ 2415986689 M001_OWCircuitStuckCV_IC4 0 "no" 1 "yes";
VAL_ 2415986689 M001_DischargeCircuitFault_IC4 0 "no" 1 "yes";
VAL_ 2415986689 M001_SM_digRedFail_IC4 0 "no" 1 "yes";
VAL_ 2415986689 M001_SM_ClrRegsFail_IC4 0 "no" 1 "yes";
VAL_ 2415949825 M001_WriteDynamicAreaANext 0 "write dynamic area B next" 1 "write dynamic area A next";
VAL_ 2416482305 M001_WriteDynamicAreaANext 0 "write dynamic area B next" 1 "write dynamic area A next";
VAL_ 2281706497 SCU1_stat_Init 0 "inactive" 1 "active";
VAL_ 2281706497 SCU1_stat_Run 0 "inactive" 1 "active";
VAL_ 2281706497 SCU1_stat_Error 0 "inactive" 1 "active";
VAL_ 2281706497 SCU1_stat_Config 0 "inactive" 1 "active";
VAL_ 2281706497 SCU1_stat_LimpHome 0 "inactive" 1 "active";
VAL_ 2281706497 SCU1_stat_Diag 0 "inactive" 1 "active";
VAL_ 2281706497 SCU1_stat_Shutdown 0 "inactive" 1 "active";
VAL_ 2281706497 SCU1_stat_ART_Started 0 "inactive" 1 "active";
VAL_ 2281706497 SCU1_stat_ART_IsActive 0 "inactive" 1 "active";
VAL_ 2281706497 SCU1_stat_ART_NoError 0 "inactive" 1 "active";
VAL_ 2281706497 SCU1_stat_ART_BMSS_Restart 0 "inactive" 1 "active";
VAL_ 2281706497 SCU1_flag_PowerContPos 0 "open" 1 "closed";
VAL_ 2281706497 SCU1_flag_PowerContNeg 0 "open" 1 "closed";
VAL_ 2281706497 SCU1_flag_PowerContPre 0 "open" 1 "closed";
VAL_ 2281706497 SCU1_flag_PowerContExtAux 0 "open" 1 "closed";
VAL_ 2281706497 SCU1_stat_ConOnProtect 0 "inactive" 1 "active";
VAL_ 2281706497 SCU1_flag_ShuntResCalibration 0 "inactive" 1 "active";
VAL_ 2281706497 SCU1_flag_EoL_Mode 0 "inactive" 1 "active";
VAL_ 2281706497 SCU1_flag_VSenserelayPosInt 0 "open" 1 "closed";
VAL_ 2281706497 SCU1_flag_VSenserelayNegInt 0 "open" 1 "closed";
VAL_ 2281706497 SCU1_flag_VSenserelayPosExt 0 "open" 1 "closed";
VAL_ 2281706497 SCU1_flag_VSenserelayNegExt 0 "open" 1 "closed";
VAL_ 2281706497 SCU1_flag_eStopLoopNotClosed 0 "closed" 1 "open";
VAL_ 2281706497 SCU1_flag_InterventioneStop 0 "not intervened" 1 "intervened";
VAL_ 2281706497 SCU1_flag_InterLockError 0 "no error" 1 "erro";
VAL_ 2281706497 SCU1_flag_SourceInterlockLoop 0 "inactive" 1 "active";
VAL_ 2281706497 SCU1_flag_KL15 0 "inactive" 1 "active";
VAL_ 2281706497 SCU1_flag_BMMSafe 0 "inactive" 1 "active";
VAL_ 2281706497 SCU1_flag_SupplyMonitorWarning 0 "supply OK" 1 "warning";
VAL_ 2281706497 SCU1_flag_CANGatewayStatus 0 "inactive" 1 "active";
VAL_ 2281706497 SCU1_flag_Led1 0 "on" 1 "off";
VAL_ 2281706497 SCU1_flag_Led2 0 "on" 1 "off";
VAL_ 2281706497 SCU1_flag_Led3 0 "on" 1 "off";
VAL_ 2281706497 SCU1_flag_Warning 0 "on" 1 "off";
VAL_ 2281706497 SCU1_flag_Alarm 0 "on" 1 "off";
VAL_ 2281706497 SCU1_flag_HSS1Locked 0 "inactive" 1 "active";
VAL_ 2281706497 SCU1_flag_HSS2Locked 0 "inactive" 1 "active";
VAL_ 2281706497 SCU1_flag_HSS3Locked 0 "inactive" 1 "active";
VAL_ 2281706497 SCU1_flag_HSS4Locked 0 "inactive" 1 "active";
VAL_ 2281706497 SCU1_flag_CompChipWarning 0 "inactive" 1 "active";
VAL_ 2281706497 SCU1_flag_PowerProtWarning 0 "inactive" 1 "active";
VAL_ 2281706497 SCU1_flag_SafetyEnable1 0 "inactive" 1 "active";
VAL_ 2281706497 SCU1_flag_SafetyEnable2 0 "inactive" 1 "active";
VAL_ 2281706497 SCU1_flag_eStopBrakeOut 0 "no eStop brake out" 1 "eStop brake out";
VAL_ 2281706497 SCU1_flag_ForceSave 0 "inactive" 1 "active";
VAL_ 2281706497 SCU1_flag_CAN1BusOff 0 "no bus off" 1 "bus off";
VAL_ 2281706497 SCU1_flag_CAN2BusOff 0 "no bus off" 1 "bus off";
VAL_ 2281706497 SCU1_flag_ContStuckChk 0 "not checked" 1 "checked";
VAL_ 2281706497 SCU1_flag_ExtAuxStuckChk 0 "not checked" 1 "checked";
VAL_ 2281706497 SCU1_flag_PrechargeOK 0 "precharge OK" 1 "precharge not OK";
VAL_ 2449523713 SCU1_wf_CellVoltageMax 0 "no" 1 "yes";
VAL_ 2449523713 SCU1_wf_CellVoltageMin 0 "no" 1 "yes";
VAL_ 2449523713 SCU1_wf_SysVoltageMax 0 "no" 1 "yes";
VAL_ 2449523713 SCU1_wf_SysVoltageMin 0 "no" 1 "yes";
VAL_ 2449523713 SCU1_wf_SysVoltageSum 0 "no" 1 "yes";
VAL_ 2449523713 SCU1_wf_ModVoltageSum 0 "no" 1 "yes";
VAL_ 2449523713 SCU1_wf_ModVoltageRefMax 0 "no" 1 "yes";
VAL_ 2449523713 SCU1_wf_Mod_Voltage_Ref_Min 0 "no" 1 "yes";
VAL_ 2449523713 SCU1_wf_IsoFaultBattNeg 0 "no" 1 "yes";
VAL_ 2449523713 SCU1_wf_IsoFaultBattPos 0 "no" 1 "yes";
VAL_ 2449523713 SCU1_wf_ContactorNegStuck 0 "no" 1 "yes";
VAL_ 2449523713 SCU1_wf_ContactorPosStuck 0 "no" 1 "yes";
VAL_ 2449523713 SCU1_wf_LVSupplyMax 0 "no" 1 "yes";
VAL_ 2449523713 SCU1_wf_LVSupplyMin 0 "no" 1 "yes";
VAL_ 2449523713 SCU1_wf_TerminalTempMax 0 "no" 1 "yes";
VAL_ 2449523713 SCU1_wf_TerminalTempMin 0 "no" 1 "yes";
VAL_ 2449523713 SCU1_wf_CellTempChargMax 0 "no" 1 "yes";
VAL_ 2449523713 SCU1_wf_CellTempChargMin 0 "no" 1 "yes";
VAL_ 2449523713 SCU1_wf_CellTempDischMax 0 "no" 1 "yes";
VAL_ 2449523713 SCU1_wf_CellTempDischMin 0 "no" 1 "yes";
VAL_ 2449523713 SCU1_wf_SysCurCha 0 "no" 1 "yes";
VAL_ 2449523713 SCU1_wf_SysCurDis 0 "no" 1 "yes";
VAL_ 2449523713 SCU1_wf_HVCurrLoopMax 0 "no" 1 "yes";
VAL_ 2449523713 SCU1_wf_HVCurrLoopMin 0 "no" 1 "yes";
VAL_ 2449523713 SCU1_wf_eStopCurrLoopMax 0 "no" 1 "yes";
VAL_ 2449523713 SCU1_wf_eStopCurrLoopMin 0 "no" 1 "yes";
VAL_ 2449523713 SCU1_wf_SysCurLimitCha 0 "no" 1 "yes";
VAL_ 2449523713 SCU1_wf_SysCurLimitDis 0 "no" 1 "yes";
VAL_ 2449523713 SCU1_wf_SysPrechargeFailed 0 "no" 1 "yes";
VAL_ 2449523713 SCU1_wf_BMMBattCom 0 "no" 1 "yes";
VAL_ 2449523713 SCU1_wf_SysInitTimeout 0 "no" 1 "yes";
VAL_ 2449523713 SCU1_wf_SCUConfig 0 "no" 1 "yes";
VAL_ 2449523713 SCU1_wf_DeepDischProt 0 "no" 1 "yes";
VAL_ 2449523713 SCU1_wf_WDReset 0 "no" 1 "yes";
VAL_ 2449523713 SCU1_wf_ExtCommunicationTout 0 "no" 1 "yes";
VAL_ 2449523713 SCU1_wf_NoAfterrunTest 0 "no" 1 "yes";
VAL_ 2449523713 SCU1_wf_CellVoltUnbalance 0 "no" 1 "yes";
VAL_ 2449523713 SCU1_wf_CellTempUnbalance 0 "no" 1 "yes";
VAL_ 2449523713 SCU1_wf_TerminalTempUnbalance 0 "no" 1 "yes";
VAL_ 2449523713 SCU1_wf_LTCError 0 "no" 1 "yes";
VAL_ 2449523713 SCU1_wf_AfterrunTest 0 "no" 1 "yes";
VAL_ 2449523713 SCU1_wf_CrossCheck 0 "no" 1 "yes";
VAL_ 2449523713 SCU1_wf_StuckAtTemp 0 "no" 1 "yes";
VAL_ 2449523713 SCU1_wf_StuckAtVolt 0 "no" 1 "yes";
VAL_ 2449523713 SCU1_wf_ProgProcess 0 "no" 1 "yes";
VAL_ 2449523713 SCU1_wf_RAM 0 "no" 1 "yes";
VAL_ 2449523713 SCU1_wf_ROM 0 "no" 1 "yes";
VAL_ 2449523713 SCU1_wf_FlashEEPROM 0 "no" 1 "yes";
VAL_ 2449523713 SCU1_wf_InvalidData 0 "no" 1 "yes";
VAL_ 2449523713 SCU1_wf_ContactorWrongState 0 "no" 1 "yes";
VAL_ 2449523713 SCU1_wf_CurrSens 0 "no" 1 "yes";
VAL_ 2449523713 SCU1_wf_ContDam 0 "no" 1 "yes";
VAL_ 2449523713 SCU1_wf_RefVoltErrorMax 0 "no" 1 "yes";
VAL_ 2449523713 SCU1_wf_RefVoltErrorMin 0 "no" 1 "yes";
VAL_ 2449523713 SCU1_wf_KL30SafeMax 0 "no" 1 "yes";
VAL_ 2449523713 SCU1_wf_KL30SafeMin 0 "no" 1 "yes";
VAL_ 2449523713 SCU1_wf_CPUSupplyWarning 0 "no" 1 "yes";
VAL_ 2449523713 SCU1_wf_PowerProtectionWarning 0 "no" 1 "yes";
VAL_ 2449523713 SCU1_wf_KL30SafeOff 0 "no" 1 "yes";
VAL_ 2449523713 SCU1_wf_Dew_Sensor 0 "no" 1 "yes";
VAL_ 2449523713 SCU1_wf_ContactorDropOut 0 "no" 1 "yes";
VAL_ 2449523713 SCU1_wf_BoardTemp 0 "no" 1 "yes";
VAL_ 2449523713 SCU1_wf_SCUError 0 "no" 1 "yes";
